VERSION "Vinfast Initial LGC"

NS_ :

BS_:

BU_: SCU BMS CHARGER HMI MCU TST

BO_ 3221225472 VECTOR__INDEPENDENT_SIG_MSG: 0 Vector__XXX
 SG_ scu_iso_signal : 0|64@0+ (1,0) [0|0] "" Vector__XXX
 SG_ scu_failflash : 0|4@0+ (1,0) [0|0] "" Vector__XXX
 SG_ SCU_Faildem1_accelerator : 0|8@0+ (1,0) [0|0] "" Vector__XXX
 SG_ bms_statusTemperaturePreFET : 0|8@0- (1,0) [-127|127] "กษ" Vector__XXX
 SG_ bms_statusTemperatureShunt : 0|8@0- (1,0) [-127|127] "กษ" Vector__XXX
 SG_ scu_commrequired_scu : 0|4@0+ (1,0) [0|15] "" Vector__XXX
 SG_ mcu_bootsubminor_version : 0|4@0+ (1,0) [0|0] "" Vector__XXX

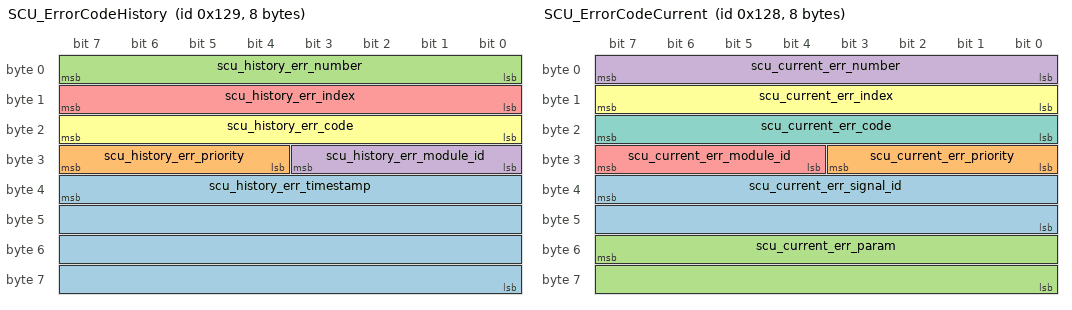
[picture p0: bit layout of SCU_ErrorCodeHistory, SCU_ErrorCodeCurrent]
BO_ 297 SCU_ErrorCodeHistory: 8 SCU
 SG_ scu_history_err_timestamp : 39|32@0+ (1,0) [0|4294967295] "" Vector__XXX
 SG_ scu_history_err_priority : 31|4@0+ (1,0) [0|15] "" Vector__XXX
 SG_ scu_history_err_number : 7|8@0+ (1,0) [0|255] "" Vector__XXX
 SG_ scu_history_err_module_id : 27|4@0+ (1,0) [0|15] "" Vector__XXX
 SG_ scu_history_err_index : 15|8@0+ (1,0) [0|255] "" Vector__XXX
 SG_ scu_history_err_code : 23|8@0+ (1,0) [0|255] "" Vector__XXX

BO_ 296 SCU_ErrorCodeCurrent: 8 SCU
 SG_ scu_current_err_signal_id : 39|16@0+ (1,0) [0|32767] "" Vector__XXX
 SG_ scu_current_err_priority : 27|4@0+ (1,0) [0|15] "" Vector__XXX
 SG_ scu_current_err_param : 55|16@0+ (1,0) [0|32767] "" Vector__XXX
 SG_ scu_current_err_number : 7|8@0+ (1,0) [0|255] "" Vector__XXX
 SG_ scu_current_err_module_id : 31|4@0+ (1,0) [0|15] "" Vector__XXX
 SG_ scu_current_err_index : 15|8@0+ (1,0) [0|255] "" Vector__XXX
 SG_ scu_current_err_code : 23|8@0- (1,0) [0|255] "" Vector__XXX

BO_ 262 SCU_Control_CHGWake: 8 SCU
 SG_ SCU_ctrl_chgWakePin : 3|4@0+ (1,0) [0|1] ""  CHARGER

BO_ 1 MCU_Iso_Message: 8 MCU
 SG_ mcu_iso_signal : 7|64@0+ (1,0) [0|0] ""  SCU

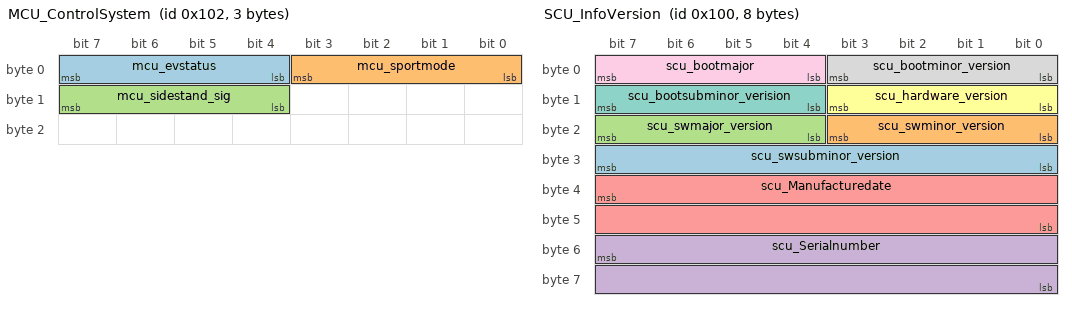
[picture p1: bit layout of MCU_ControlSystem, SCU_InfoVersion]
BO_ 258 MCU_ControlSystem: 3 MCU
 SG_ mcu_evstatus : 7|4@0+ (1,0) [0|0] ""  HMI,SCU
 SG_ mcu_sportmode : 3|4@0+ (1,0) [0|15] ""  HMI,SCU
 SG_ mcu_sidestand_sig : 15|4@0- (1,0) [0|1] ""  HMI,SCU

BO_ 256 SCU_InfoVersion: 8 SCU
 SG_ scu_swsubminor_version : 31|8@0+ (1,0) [0|0] "" Vector__XXX
 SG_ scu_swminor_version : 19|4@0+ (1,0) [0|0] "" Vector__XXX
 SG_ scu_swmajor_version : 23|4@0+ (1,0) [0|0] "" Vector__XXX
 SG_ scu_Serialnumber : 55|16@0+ (1,0) [0|0] "" Vector__XXX
 SG_ scu_Manufacturedate : 39|16@0+ (1,0) [0|0] "" Vector__XXX
 SG_ scu_hardware_version : 11|4@0+ (1,0) [0|0] "" Vector__XXX
 SG_ scu_bootsubminor_verision : 15|4@0+ (1,0) [0|0] "" Vector__XXX
 SG_ scu_bootminor_version : 3|4@0+ (1,0) [0|0] "" Vector__XXX
 SG_ scu_bootmajor : 7|4@0+ (1,0) [0|0] "" Vector__XXX

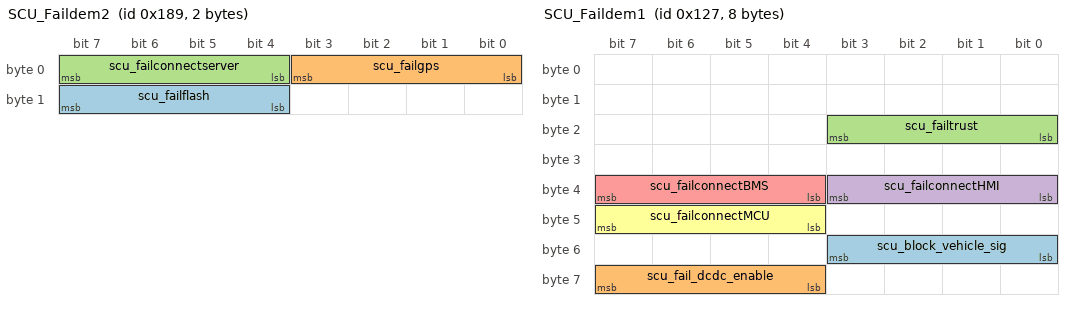
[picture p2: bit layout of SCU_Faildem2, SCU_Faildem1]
BO_ 393 SCU_Faildem2: 2 SCU
 SG_ scu_failflash : 15|4@0+ (1,0) [0|0] ""  HMI
 SG_ scu_failgps : 3|4@0+ (1,0) [0|0] ""  HMI
 SG_ scu_failconnectserver : 7|4@0+ (1,0) [0|0] ""  HMI

BO_ 295 SCU_Faildem1: 8 SCU
 SG_ scu_block_vehicle_sig : 51|4@0+ (1,0) [0|15] ""  HMI
 SG_ scu_fail_dcdc_enable : 63|4@0+ (1,0) [0|15] ""  HMI
 SG_ scu_failtrust : 19|4@0+ (1,0) [0|0] ""  HMI
 SG_ scu_failconnectHMI : 35|4@0+ (1,0) [0|0] ""  HMI
 SG_ scu_failconnectBMS : 39|4@0+ (1,0) [0|0] ""  HMI
 SG_ scu_failconnectMCU : 47|4@0+ (1,0) [0|0] ""  HMI

BO_ 386 SCU_Timestamp: 5 SCU
 SG_ scu_Time_Format : 39|4@0+ (1,0) [0|1] ""  HMI
 SG_ scu_epochtimestamp : 7|32@0+ (1,0) [0|0] ""  HMI

BO_ 270 SCU_Control_MCUData2: 8 SCU
 SG_ scu_ctrl_mcu_data2 : 7|64@0+ (1,0) [0|0] ""  MCU

BO_ 269 SCU_Control_MCUData1: 8 SCU
 SG_ scu_ctrl_mcu_data1 : 7|64@0+ (1,0) [0|0] ""  MCU

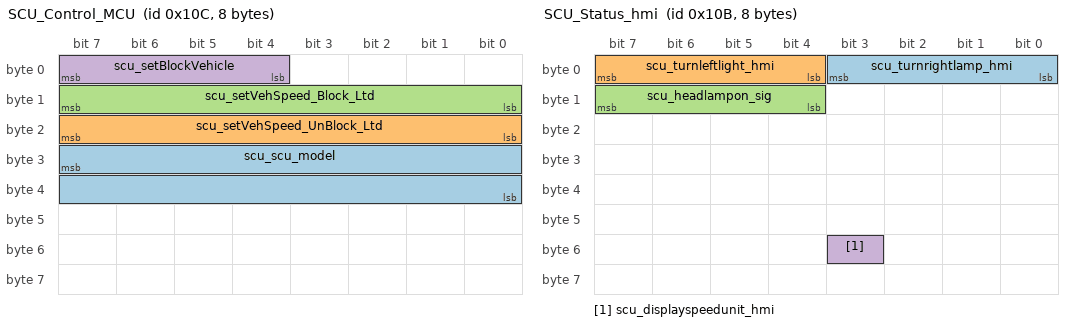
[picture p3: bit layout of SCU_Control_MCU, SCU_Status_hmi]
BO_ 268 SCU_Control_MCU: 8 SCU
 SG_ scu_scu_model : 31|16@0+ (1,0) [0|0] ""  MCU
 SG_ scu_setVehSpeed_UnBlock_Ltd : 23|8@0+ (1,0) [0|0] ""  MCU
 SG_ scu_setVehSpeed_Block_Ltd : 15|8@0+ (1,0) [0|0] ""  MCU
 SG_ scu_setBlockVehicle : 7|4@0+ (1,0) [0|0] ""  MCU

BO_ 517 MCU_SyncTimeData: 8 MCU
 SG_ mcu_sync_time_data : 7|64@0+ (1,0) [0|0] ""  SCU

BO_ 267 SCU_Status_hmi: 8 SCU
 SG_ scu_turnrightlamp_hmi : 3|4@0- (1,0) [0|0] ""  HMI
 SG_ scu_turnleftlight_hmi : 7|4@0+ (1,0) [0|0] ""  HMI
 SG_ scu_headlampon_sig : 15|4@0+ (1,0) [0|0] ""  HMI
 SG_ scu_displayspeedunit_hmi : 51|1@0+ (1,0) [0|0] ""  HMI

BO_ 261 SCU_Debug_Msg: 8 SCU
 SG_ SCU_state : 7|4@0+ (1,0) [0|0] "" Vector__XXX
 SG_ SCU_IG_status : 3|4@0+ (1,0) [0|0] "" Vector__XXX

BO_ 515 MCU_Request_ODO: 1 MCU
 SG_ mcu_request_odo_sig : 7|8@0+ (1,0) [0|0] ""  SCU

BO_ 264 SCU_SyncODO: 4 SCU
 SG_ scu_total_ODO : 7|32@0+ (1,0) [0|0] ""  MCU

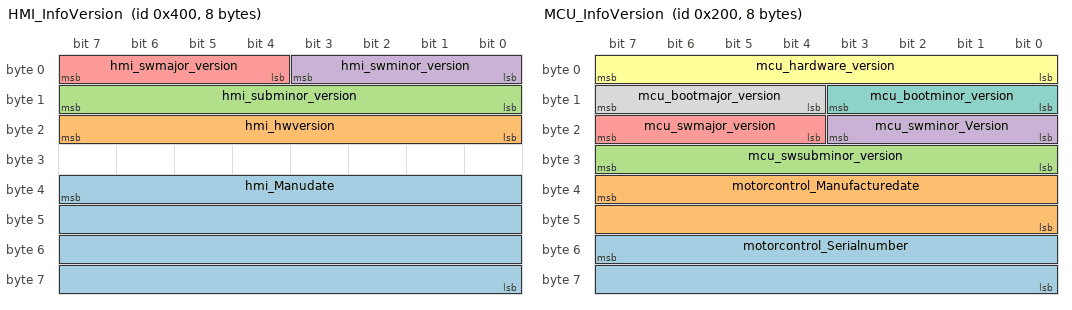
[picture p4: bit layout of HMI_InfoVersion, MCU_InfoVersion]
BO_ 1024 HMI_InfoVersion: 8 HMI
 SG_ hmi_Manudate : 39|32@0+ (1,0) [0|0] ""  SCU
 SG_ hmi_hwversion : 23|8@0+ (1,0) [0|0] ""  SCU
 SG_ hmi_subminor_version : 15|8@0+ (1,0) [0|0] ""  SCU
 SG_ hmi_swminor_version : 3|4@0+ (1,0) [0|0] ""  SCU
 SG_ hmi_swmajor_version : 7|4@0+ (1,0) [0|0] ""  SCU

BO_ 1026 HMI_Faildem: 1 HMI
 SG_ hmi_fail_canmcu : 7|4@0+ (1,0) [0|0] ""  SCU

BO_ 512 MCU_InfoVersion: 8 MCU
 SG_ motorcontrol_Serialnumber : 55|16@0+ (1,0) [0|0] ""  SCU
 SG_ motorcontrol_Manufacturedate : 39|16@0+ (1,0) [0|65535] ""  SCU
 SG_ mcu_swsubminor_version : 31|8@0+ (1,0) [0|255] ""  SCU
 SG_ mcu_swminor_Version : 19|4@0+ (1,0) [0|15] ""  SCU
 SG_ mcu_swmajor_version : 23|4@0+ (1,0) [0|0] ""  SCU
 SG_ mcu_hardware_version : 7|8@0+ (1,0) [0|0] ""  SCU
 SG_ mcu_bootminor_version : 11|4@0+ (1,0) [0|0] ""  SCU
 SG_ mcu_bootmajor_version : 15|4@0+ (1,0) [0|0] ""  SCU

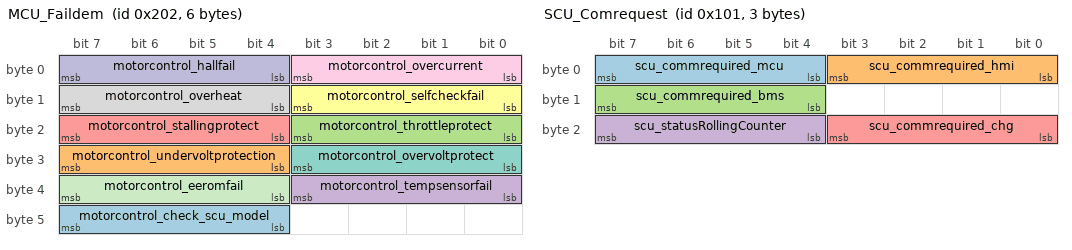
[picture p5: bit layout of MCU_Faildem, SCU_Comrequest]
BO_ 514 MCU_Faildem: 6 MCU
 SG_ motorcontrol_check_scu_model : 47|4@0+ (1,0) [0|0] ""  HMI,SCU
 SG_ motorcontrol_undervoltprotection : 31|4@0+ (1,0) [0|0] ""  SCU,HMI
 SG_ motorcontrol_throttleprotect : 19|4@0+ (1,0) [0|0] ""  SCU,HMI
 SG_ motorcontrol_tempsensorfail : 35|4@0+ (1,0) [0|0] ""  SCU,HMI
 SG_ motorcontrol_stallingprotect : 23|4@0+ (1,0) [0|0] ""  SCU,HMI
 SG_ motorcontrol_selfcheckfail : 11|4@0+ (1,0) [0|0] ""  SCU,HMI
 SG_ motorcontrol_overvoltprotect : 27|4@0+ (1,0) [0|0] ""  SCU,HMI
 SG_ motorcontrol_overheat : 15|4@0+ (1,0) [0|0] ""  SCU,HMI
 SG_ motorcontrol_overcurrent : 3|4@0+ (1,0) [0|0] ""  SCU,HMI
 SG_ motorcontrol_hallfail : 7|4@0+ (1,0) [0|15] ""  SCU,HMI
 SG_ motorcontrol_eeromfail : 39|4@0+ (1,0) [0|15] ""  SCU,HMI

BO_ 782 BMS_InfoContactor: 8 BMS
 SG_ bms_statusAdcPackVolt : 7|16@0+ (0.01,0) [0|655.35] "10mV"  SCU
 SG_ bms_statusAdcAfterFuseVolt : 39|16@0+ (0.01,0) [0|655.35] "10mV"  SCU
 SG_ bms_statusAdcAfterContactorVolt : 23|16@0+ (0.01,0) [0|655.35] "10mV"  SCU

BO_ 795 BMS_InfoVoltageCell6: 8 BMS
 SG_ bms_statusVoltageCell22 : 23|16@0+ (0.0001,0) [0|6.5535] "V"  SCU
 SG_ bms_statusVoltageCell21 : 7|16@0+ (0.0001,0) [0|6.5535] "V"  SCU

BO_ 794 BMS_InfoVoltageCell5: 8 BMS
 SG_ bms_statusVoltageCell20 : 55|16@0+ (0.0001,0) [0|6.5535] "V"  SCU
 SG_ bms_statusVoltageCell19 : 39|16@0+ (0.0001,0) [0|6.5535] "V"  SCU
 SG_ bms_statusVoltageCell18 : 23|16@0+ (0.0001,0) [0|6.5535] "V" Vector__XXX
 SG_ bms_statusVoltageCell17 : 7|16@0+ (0.0001,0) [0|6.5535] "V" Vector__XXX

BO_ 257 SCU_Comrequest: 3 SCU
 SG_ scu_commrequired_mcu : 7|4@0+ (1,0) [0|15] ""  MCU
 SG_ scu_commrequired_hmi : 3|4@0+ (1,0) [0|15] ""  HMI
 SG_ scu_commrequired_bms : 15|4@0+ (1,0) [0|15] ""  BMS
 SG_ scu_statusRollingCounter : 23|4@0+ (1,0) [0|15] "" Vector__XXX
 SG_ scu_commrequired_chg : 19|4@0+ (1,0) [0|15] ""  CHARGER

BO_ 271 SCU_info: 8 SCU
 SG_ scu_ignitionstatus_bms : 7|4@0+ (1,0) [0|15] ""  BMS
 SG_ scu_sendrollingcounter_bms : 3|4@0+ (1,0) [0|15] ""  BMS

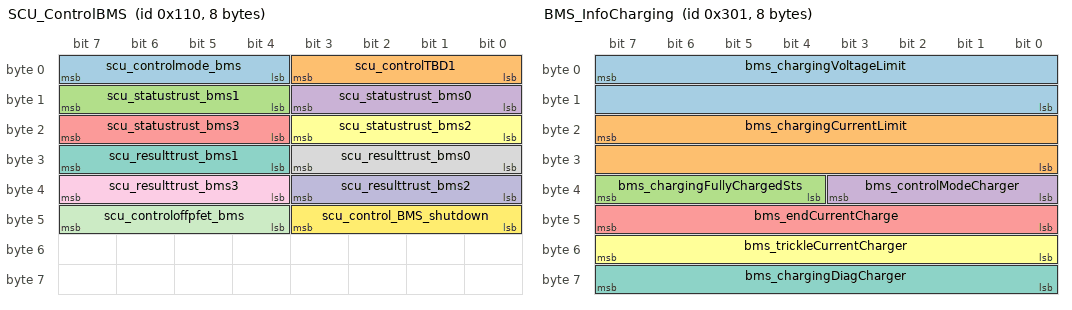
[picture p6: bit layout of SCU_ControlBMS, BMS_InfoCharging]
BO_ 272 SCU_ControlBMS: 8 SCU
 SG_ scu_controlmode_bms : 7|4@0+ (1,0) [0|15] ""  BMS
 SG_ scu_controlTBD1 : 3|4@0+ (1,0) [0|15] ""  BMS
 SG_ scu_statustrust_bms1 : 15|4@0+ (1,0) [0|15] ""  BMS
 SG_ scu_statustrust_bms0 : 11|4@0+ (1,0) [0|15] ""  BMS
 SG_ scu_statustrust_bms3 : 23|4@0+ (1,0) [0|15] ""  BMS
 SG_ scu_statustrust_bms2 : 19|4@0+ (1,0) [0|15] ""  BMS
 SG_ scu_resulttrust_bms1 : 31|4@0+ (1,0) [0|15] ""  BMS
 SG_ scu_resulttrust_bms0 : 27|4@0+ (1,0) [0|15] ""  BMS
 SG_ scu_resulttrust_bms3 : 39|4@0+ (1,0) [0|15] ""  BMS
 SG_ scu_resulttrust_bms2 : 35|4@0+ (1,0) [0|15] ""  BMS
 SG_ scu_controloffpfet_bms : 47|4@0+ (1,0) [0|15] ""  BMS
 SG_ scu_control_BMS_shutdown : 43|4@0+ (1,0) [0|15] ""  BMS

BO_ 2 BMS_ISO_Message: 8 BMS
 SG_ bms_iso_signal : 7|64@0+ (1,0) [0|1.84467440737096E+019] ""  CHARGER,SCU

BO_ 513 MCU_Infostatus: 8 MCU
 SG_ mcu_speedkmh : 7|16@0+ (1,0) [0|65535] ""  HMI,SCU
 SG_ mcu_totalODO : 23|32@0+ (1,0) [0|4294967295] ""  BMS,SCU,HMI
 SG_ mcu_brakesignal : 63|4@0+ (1,0) [0|15] ""  HMI

BO_ 768 BMS_ControlSystem: 8 BMS
 SG_ bms_controlSysMaxChgCurrent : 7|16@0- (0.02,0) [-655|655] "A"  CHARGER,MCU,SCU
 SG_ bms_controlSysMaxDsgCurrent : 23|16@0- (0.02,0) [-655|655] "A"  CHARGER,MCU,SCU
 SG_ bms_controlSysMaxChgPower : 39|16@0- (1,0) [-32767|32767] "W"  CHARGER,MCU,SCU
 SG_ bms_controlSysMaxDsgPower : 55|16@0- (1,0) [-32767|32767] "W"  CHARGER,MCU,SCU

BO_ 769 BMS_InfoCharging: 8 BMS
 SG_ bms_chargingVoltageLimit : 7|16@0+ (0.002,0) [0|131.07] "V"  CHARGER
 SG_ bms_chargingCurrentLimit : 23|16@0- (0.02,0) [-655|655] "A"  CHARGER
 SG_ bms_chargingFullyChargedSts : 39|4@0+ (1,0) [0|15] ""  CHARGER
 SG_ bms_controlModeCharger : 35|4@0+ (1,0) [0|15] ""  CHARGER
 SG_ bms_endCurrentCharge : 47|8@0+ (0.01,0) [0|2.55] "A"  CHARGER
 SG_ bms_trickleCurrentCharger : 55|8@0+ (0.01,0) [0|2.55] "A"  CHARGER
 SG_ bms_chargingDiagCharger : 63|8@0+ (1,0) [0|255] ""  CHARGER

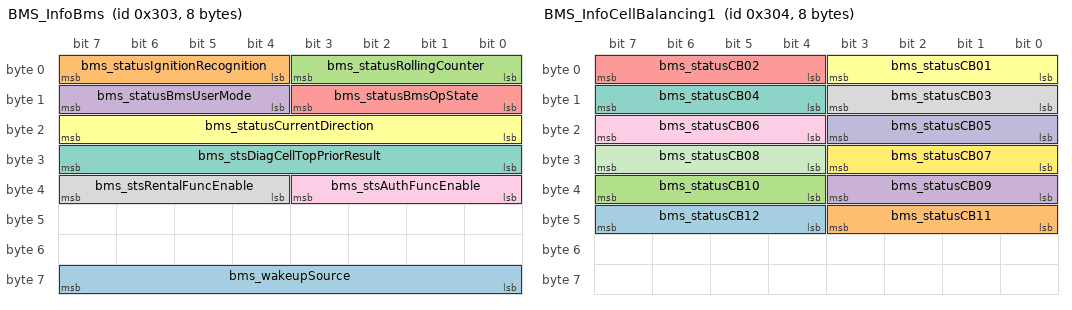
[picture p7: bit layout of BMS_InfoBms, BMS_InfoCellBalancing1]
BO_ 771 BMS_InfoBms: 8 BMS
 SG_ bms_wakeupSource : 63|8@0+ (1,0) [0|0] ""  SCU
 SG_ bms_statusIgnitionRecognition : 7|4@0+ (1,0) [0|15] ""  CHARGER,SCU
 SG_ bms_statusRollingCounter : 3|4@0+ (1,0) [0|15] ""  CHARGER,SCU
 SG_ bms_statusBmsUserMode : 15|4@0+ (1,0) [0|15] ""  CHARGER,SCU
 SG_ bms_statusBmsOpState : 11|4@0+ (1,0) [0|15] ""  CHARGER,SCU
 SG_ bms_statusCurrentDirection : 23|8@0+ (1,0) [0|255] ""  CHARGER,SCU
 SG_ bms_stsDiagCellTopPriorResult : 31|8@0+ (1,0) [0|255] ""  CHARGER,SCU
 SG_ bms_stsRentalFuncEnable : 39|4@0+ (1,0) [0|15] ""  CHARGER,SCU
 SG_ bms_stsAuthFuncEnable : 35|4@0+ (1,0) [0|15] ""  CHARGER,SCU

BO_ 772 BMS_InfoCellBalancing1: 8 BMS
 SG_ bms_statusCB12 : 47|4@0+ (1,0) [0|15] "" Vector__XXX
 SG_ bms_statusCB11 : 43|4@0+ (1,0) [0|15] "" Vector__XXX
 SG_ bms_statusCB10 : 39|4@0+ (1,0) [0|15] "" Vector__XXX
 SG_ bms_statusCB09 : 35|4@0+ (1,0) [0|15] "" Vector__XXX
 SG_ bms_statusCB02 : 7|4@0+ (1,0) [0|15] ""  SCU
 SG_ bms_statusCB01 : 3|4@0+ (1,0) [0|15] ""  SCU
 SG_ bms_statusCB04 : 15|4@0+ (1,0) [0|15] ""  SCU
 SG_ bms_statusCB03 : 11|4@0+ (1,0) [0|15] ""  SCU
 SG_ bms_statusCB06 : 23|4@0+ (1,0) [0|15] ""  SCU
 SG_ bms_statusCB05 : 19|4@0+ (1,0) [0|15] ""  SCU
 SG_ bms_statusCB08 : 31|4@0+ (1,0) [0|15] ""  SCU
 SG_ bms_statusCB07 : 27|4@0+ (1,0) [0|15] ""  SCU

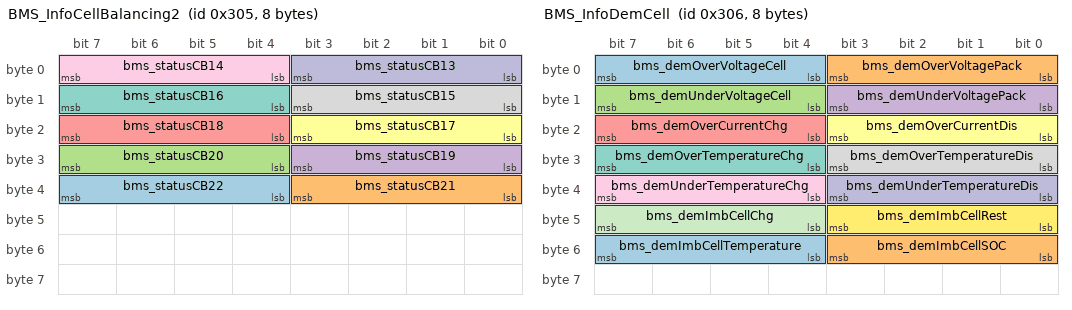
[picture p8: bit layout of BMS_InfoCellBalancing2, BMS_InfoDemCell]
BO_ 773 BMS_InfoCellBalancing2: 8 BMS
 SG_ bms_statusCB22 : 39|4@0+ (1,0) [0|15] ""  SCU
 SG_ bms_statusCB21 : 35|4@0+ (1,0) [0|15] ""  SCU
 SG_ bms_statusCB20 : 31|4@0+ (1,0) [0|15] ""  SCU
 SG_ bms_statusCB19 : 27|4@0+ (1,0) [0|15] ""  SCU
 SG_ bms_statusCB18 : 23|4@0+ (1,0) [0|15] "" Vector__XXX
 SG_ bms_statusCB17 : 19|4@0+ (1,0) [0|15] "" Vector__XXX
 SG_ bms_statusCB16 : 15|4@0+ (1,0) [0|15] "" Vector__XXX
 SG_ bms_statusCB15 : 11|4@0+ (1,0) [0|15] "" Vector__XXX
 SG_ bms_statusCB14 : 7|4@0+ (1,0) [0|15] ""  SCU
 SG_ bms_statusCB13 : 3|4@0+ (1,0) [0|15] ""  SCU

BO_ 774 BMS_InfoDemCell: 8 BMS
 SG_ bms_demOverVoltageCell : 7|4@0+ (1,0) [0|15] ""  HMI,SCU
 SG_ bms_demOverVoltagePack : 3|4@0+ (1,0) [0|15] ""  HMI,SCU
 SG_ bms_demUnderVoltageCell : 15|4@0+ (1,0) [0|15] ""  HMI,SCU
 SG_ bms_demUnderVoltagePack : 11|4@0+ (1,0) [0|15] ""  HMI,SCU
 SG_ bms_demOverCurrentChg : 23|4@0+ (1,0) [0|15] ""  HMI,SCU
 SG_ bms_demOverCurrentDis : 19|4@0+ (1,0) [0|15] ""  HMI,SCU
 SG_ bms_demOverTemperatureChg : 31|4@0+ (1,0) [0|15] ""  HMI,SCU
 SG_ bms_demOverTemperatureDis : 27|4@0+ (1,0) [0|15] ""  HMI,SCU
 SG_ bms_demUnderTemperatureChg : 39|4@0+ (1,0) [0|15] ""  HMI,SCU
 SG_ bms_demUnderTemperatureDis : 35|4@0+ (1,0) [0|15] ""  HMI,SCU
 SG_ bms_demImbCellChg : 47|4@0+ (1,0) [0|15] ""  HMI,SCU
 SG_ bms_demImbCellRest : 43|4@0+ (1,0) [0|15] ""  HMI,SCU
 SG_ bms_demImbCellTemperature : 55|4@0+ (1,0) [0|15] ""  HMI,SCU
 SG_ bms_demImbCellSOC : 51|4@0+ (1,0) [0|15] ""  HMI,SCU

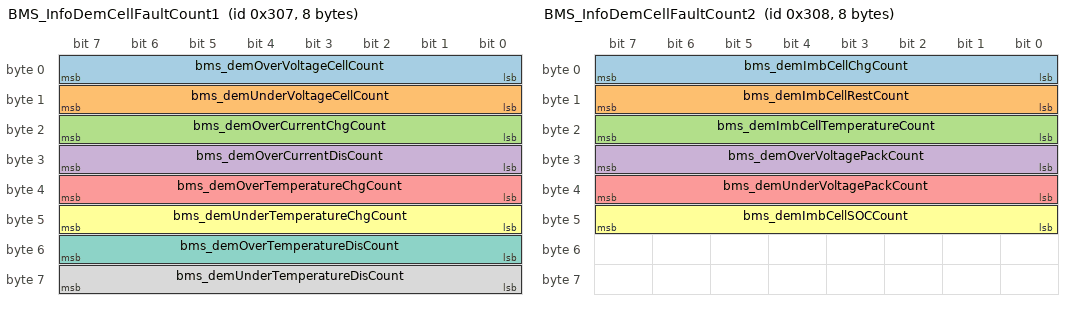
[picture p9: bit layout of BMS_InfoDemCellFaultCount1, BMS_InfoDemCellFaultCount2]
BO_ 775 BMS_InfoDemCellFaultCount1: 8 BMS
 SG_ bms_demOverVoltageCellCount : 7|8@0+ (1,0) [0|255] ""  SCU
 SG_ bms_demUnderVoltageCellCount : 15|8@0+ (1,0) [0|255] ""  SCU
 SG_ bms_demOverCurrentChgCount : 23|8@0+ (1,0) [0|255] ""  SCU
 SG_ bms_demOverCurrentDisCount : 31|8@0+ (1,0) [0|255] ""  SCU
 SG_ bms_demOverTemperatureChgCount : 39|8@0+ (1,0) [0|255] ""  SCU
 SG_ bms_demUnderTemperatureChgCount : 47|8@0+ (1,0) [0|255] ""  SCU
 SG_ bms_demOverTemperatureDisCount : 55|8@0+ (1,0) [0|255] ""  SCU
 SG_ bms_demUnderTemperatureDisCount : 63|8@0+ (1,0) [0|255] ""  SCU

BO_ 776 BMS_InfoDemCellFaultCount2: 8 BMS
 SG_ bms_demImbCellChgCount : 7|8@0+ (1,0) [0|255] ""  SCU
 SG_ bms_demImbCellRestCount : 15|8@0+ (1,0) [0|255] ""  SCU
 SG_ bms_demImbCellTemperatureCount : 23|8@0+ (1,0) [0|255] ""  SCU
 SG_ bms_demOverVoltagePackCount : 31|8@0+ (1,0) [0|255] ""  SCU
 SG_ bms_demUnderVoltagePackCount : 39|8@0+ (1,0) [0|255] ""  SCU
 SG_ bms_demImbCellSOCCount : 47|8@0+ (1,0) [0|255] ""  SCU

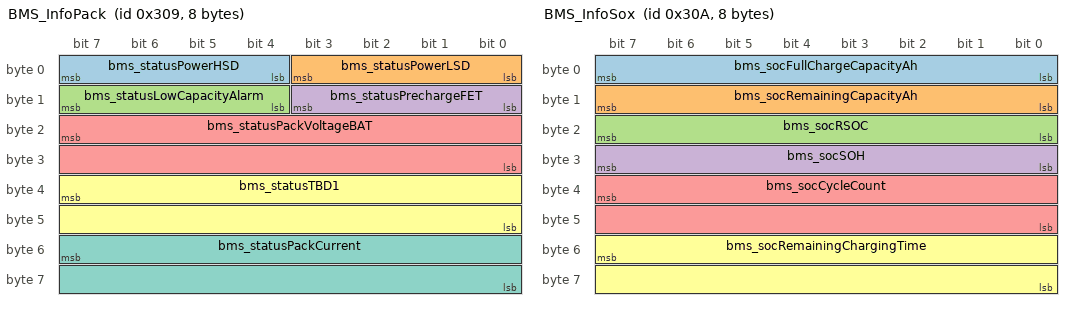
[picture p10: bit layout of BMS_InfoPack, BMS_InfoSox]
BO_ 777 BMS_InfoPack: 8 BMS
 SG_ bms_statusPowerHSD : 7|4@0+ (1,0) [0|15] ""  CHARGER,SCU
 SG_ bms_statusPowerLSD : 3|4@0+ (1,0) [0|15] ""  CHARGER,SCU
 SG_ bms_statusLowCapacityAlarm : 15|4@0+ (1,0) [0|15] ""  CHARGER,SCU
 SG_ bms_statusPrechargeFET : 11|4@0+ (1,0) [0|15] ""  CHARGER,SCU
 SG_ bms_statusPackVoltageBAT : 23|16@0+ (0.002,0) [0|131.07] "V"  CHARGER,HMI,SCU
 SG_ bms_statusTBD1 : 39|16@0+ (1,0) [0|65535] ""  CHARGER,HMI,SCU
 SG_ bms_statusPackCurrent : 55|16@0- (0.02,0) [-655.36|655.34] "A"  CHARGER,HMI,SCU

BO_ 778 BMS_InfoSox: 8 BMS
 SG_ bms_socFullChargeCapacityAh : 7|8@0+ (0.4,0) [0|76.5] "Ah"  CHARGER,SCU
 SG_ bms_socRemainingCapacityAh : 15|8@0+ (0.4,0) [0|102] "Ah"  CHARGER,SCU
 SG_ bms_socRSOC : 23|8@0+ (1,0) [0|255] "%"  CHARGER,HMI,SCU
 SG_ bms_socSOH : 31|8@0+ (1,0) [0|255] "%"  CHARGER,HMI,SCU
 SG_ bms_socCycleCount : 39|16@0+ (1,0) [0|65535] ""  CHARGER,HMI,SCU
 SG_ bms_socRemainingChargingTime : 55|16@0+ (1,0) [0|65535] "min"  CHARGER,HMI,SCU

BO_ 779 BMS_InfoAccumDsgChgCapacity: 8 BMS
 SG_ bms_AccumChargeCapacityAh : 7|32@0+ (1,0) [0|4294967295] "Ah"  SCU
 SG_ bms_AccumDischargeCapacityAh : 39|32@0+ (1,0) [0|4294967295] "Ah"  SCU

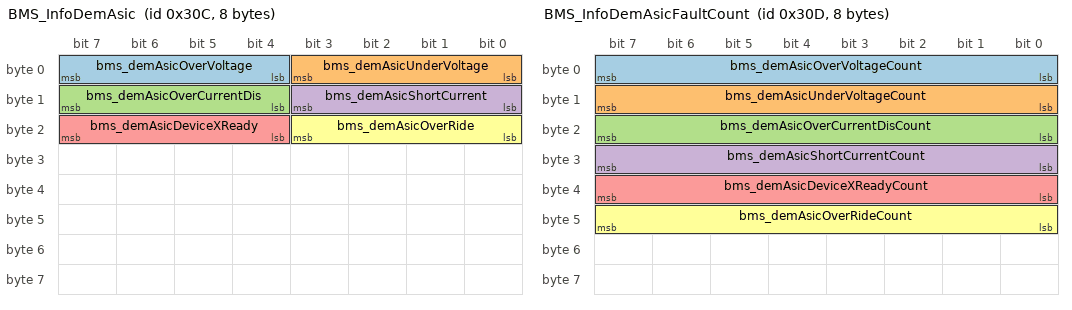
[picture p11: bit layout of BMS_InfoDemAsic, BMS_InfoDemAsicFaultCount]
BO_ 780 BMS_InfoDemAsic: 8 BMS
 SG_ bms_demAsicOverVoltage : 7|4@0+ (1,0) [0|15] ""  HMI,SCU
 SG_ bms_demAsicUnderVoltage : 3|4@0+ (1,0) [0|15] ""  HMI,SCU
 SG_ bms_demAsicOverCurrentDis : 15|4@0+ (1,0) [0|15] ""  HMI,SCU
 SG_ bms_demAsicShortCurrent : 11|4@0+ (1,0) [0|15] ""  HMI,SCU
 SG_ bms_demAsicDeviceXReady : 23|4@0+ (1,0) [0|15] ""  HMI,SCU
 SG_ bms_demAsicOverRide : 19|4@0+ (1,0) [0|15] ""  HMI,SCU

BO_ 781 BMS_InfoDemAsicFaultCount: 8 BMS
 SG_ bms_demAsicOverVoltageCount : 7|8@0+ (1,0) [0|255] ""  SCU
 SG_ bms_demAsicUnderVoltageCount : 15|8@0+ (1,0) [0|255] ""  SCU
 SG_ bms_demAsicOverCurrentDisCount : 23|8@0+ (1,0) [0|255] ""  SCU
 SG_ bms_demAsicShortCurrentCount : 31|8@0+ (1,0) [0|255] ""  SCU
 SG_ bms_demAsicDeviceXReadyCount : 39|8@0+ (1,0) [0|255] "" Vector__XXX
 SG_ bms_demAsicOverRideCount : 47|8@0+ (1,0) [0|255] ""  SCU

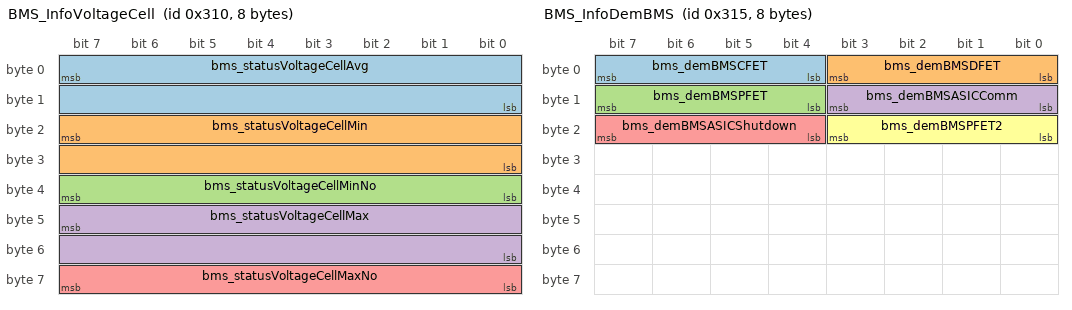
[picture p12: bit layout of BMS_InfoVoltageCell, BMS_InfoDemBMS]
BO_ 784 BMS_InfoVoltageCell: 8 BMS
 SG_ bms_statusVoltageCellAvg : 7|16@0+ (0.0001,0) [0|6.5535] "V"  SCU
 SG_ bms_statusVoltageCellMin : 23|16@0+ (0.0001,0) [0|6.5535] "V"  SCU
 SG_ bms_statusVoltageCellMinNo : 39|8@0+ (1,0) [0|255] "Bank"  SCU
 SG_ bms_statusVoltageCellMax : 47|16@0+ (0.0001,0) [0|6.5535] "V"  SCU
 SG_ bms_statusVoltageCellMaxNo : 63|8@0+ (1,0) [0|255] "Bank"  SCU

BO_ 785 BMS_InfoVoltageCell1: 8 BMS
 SG_ bms_statusVoltageCell01 : 7|16@0+ (0.0001,0) [0|6.5535] "V"  SCU
 SG_ bms_statusVoltageCell02 : 23|16@0+ (0.0001,0) [0|6.5535] "V"  SCU
 SG_ bms_statusVoltageCell03 : 39|16@0+ (0.0001,0) [0|6.5535] "V"  SCU
 SG_ bms_statusVoltageCell04 : 55|16@0+ (0.0001,0) [0|6.5535] "V"  SCU

BO_ 786 BMS_InfoVoltageCell2: 8 BMS
 SG_ bms_statusVoltageCell05 : 7|16@0+ (0.0001,0) [0|6.5535] "V"  SCU
 SG_ bms_statusVoltageCell06 : 23|16@0+ (0.0001,0) [0|6.5535] "V"  SCU
 SG_ bms_statusVoltageCell07 : 39|16@0+ (0.0001,0) [0|6.5535] "V"  SCU
 SG_ bms_statusVoltageCell08 : 55|16@0+ (0.0001,0) [0|6.5535] "V"  SCU

BO_ 787 BMS_InfoVoltageCell3: 8 BMS
 SG_ bms_statusVoltageCell09 : 7|16@0+ (0.0001,0) [0|6.5535] "V"  SCU
 SG_ bms_statusVoltageCell10 : 23|16@0+ (0.0001,0) [0|6.5535] "V"  SCU
 SG_ bms_statusVoltageCell11 : 39|16@0+ (0.0001,0) [0|6.5535] "V"  SCU
 SG_ bms_statusVoltageCell12 : 55|16@0+ (0.0001,0) [0|6.5535] "V"  SCU

BO_ 788 BMS_InfoVoltageCell4: 8 BMS
 SG_ bms_statusVoltageCell16 : 55|16@0+ (0.0001,0) [0|6.5535] "V" Vector__XXX
 SG_ bms_statusVoltageCell15 : 39|16@0+ (0.0001,0) [0|6.5535] "V" Vector__XXX
 SG_ bms_statusVoltageCell13 : 7|16@0+ (0.0001,0) [0|6.5535] "V"  SCU
 SG_ bms_statusVoltageCell14 : 23|16@0+ (0.0001,0) [0|6.5535] "V"  SCU

BO_ 789 BMS_InfoDemBMS: 8 BMS
 SG_ bms_demBMSCFET : 7|4@0+ (1,0) [0|15] ""  HMI,SCU
 SG_ bms_demBMSDFET : 3|4@0+ (1,0) [0|15] ""  HMI,SCU
 SG_ bms_demBMSPFET : 15|4@0+ (1,0) [0|15] ""  HMI,SCU
 SG_ bms_demBMSASICComm : 11|4@0+ (1,0) [0|15] ""  HMI,SCU
 SG_ bms_demBMSASICShutdown : 23|4@0+ (1,0) [0|15] ""  HMI,SCU
 SG_ bms_demBMSPFET2 : 19|4@0+ (1,0) [0|15] ""  SCU

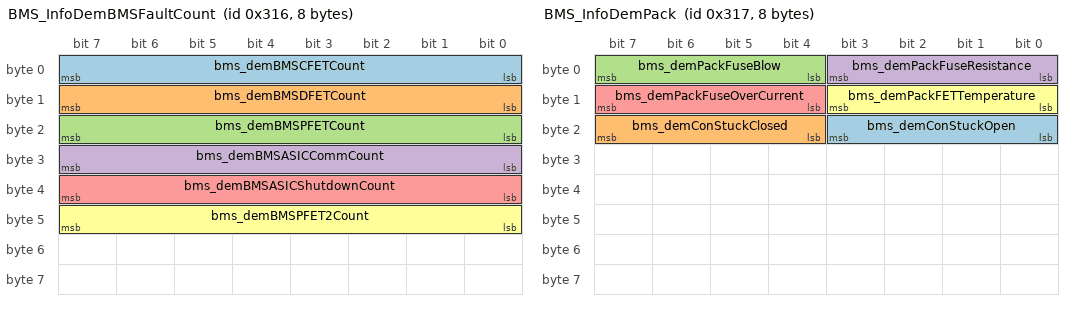
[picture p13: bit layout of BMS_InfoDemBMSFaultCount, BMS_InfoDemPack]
BO_ 790 BMS_InfoDemBMSFaultCount: 8 BMS
 SG_ bms_demBMSCFETCount : 7|8@0+ (1,0) [0|255] ""  SCU
 SG_ bms_demBMSDFETCount : 15|8@0+ (1,0) [0|255] ""  SCU
 SG_ bms_demBMSPFETCount : 23|8@0+ (1,0) [0|255] ""  SCU
 SG_ bms_demBMSASICCommCount : 31|8@0+ (1,0) [0|255] ""  SCU
 SG_ bms_demBMSASICShutdownCount : 39|8@0+ (1,0) [0|255] ""  SCU
 SG_ bms_demBMSPFET2Count : 47|8@0+ (1,0) [0|255] ""  SCU

BO_ 791 BMS_InfoDemPack: 8 BMS
 SG_ bms_demConStuckOpen : 19|4@0+ (1,0) [0|15] ""  SCU
 SG_ bms_demConStuckClosed : 23|4@0+ (1,0) [0|15] ""  SCU
 SG_ bms_demPackFuseBlow : 7|4@0+ (1,0) [0|15] ""  HMI,SCU
 SG_ bms_demPackFuseResistance : 3|4@0+ (1,0) [0|15] ""  HMI,SCU
 SG_ bms_demPackFuseOverCurrent : 15|4@0+ (1,0) [0|15] ""  HMI,SCU
 SG_ bms_demPackFETTemperature : 11|4@0+ (1,0) [0|15] ""  HMI,SCU

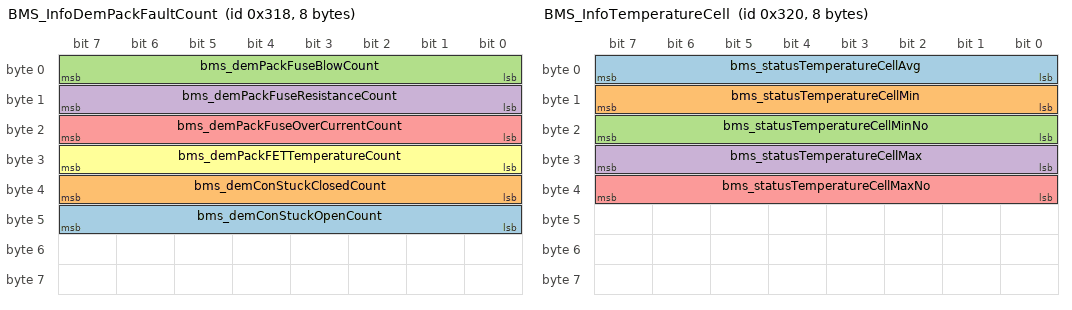
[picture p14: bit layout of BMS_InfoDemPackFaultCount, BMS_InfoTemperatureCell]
BO_ 792 BMS_InfoDemPackFaultCount: 8 BMS
 SG_ bms_demConStuckOpenCount : 47|8@0+ (1,0) [0|255] ""  SCU
 SG_ bms_demConStuckClosedCount : 39|8@0+ (1,0) [0|255] ""  SCU
 SG_ bms_demPackFuseBlowCount : 7|8@0+ (1,0) [0|255] ""  SCU
 SG_ bms_demPackFuseResistanceCount : 15|8@0+ (1,0) [0|255] ""  SCU
 SG_ bms_demPackFuseOverCurrentCount : 23|8@0+ (1,0) [0|255] ""  SCU
 SG_ bms_demPackFETTemperatureCount : 31|8@0+ (1,0) [0|255] ""  SCU

BO_ 793 BMS_InfoMileage: 8 BMS
 SG_ bms_mileage_data : 7|32@0+ (1,0) [0|4294967295] ""  SCU
 SG_ bms_mileageTBD1 : 39|32@0+ (1,0) [0|4294967295] ""  SCU

BO_ 800 BMS_InfoTemperatureCell: 8 BMS
 SG_ bms_statusTemperatureCellAvg : 7|8@0- (1,0) [-127|127] "กษ"  HMI,SCU
 SG_ bms_statusTemperatureCellMin : 15|8@0- (1,0) [-127|127] "กษ"  SCU
 SG_ bms_statusTemperatureCellMinNo : 23|8@0+ (1,0) [0|255] "Th"  SCU
 SG_ bms_statusTemperatureCellMax : 31|8@0- (1,0) [-127|127] "กษ"  HMI,SCU
 SG_ bms_statusTemperatureCellMaxNo : 39|8@0+ (1,0) [0|255] "Th"  SCU

BO_ 801 BMS_InfoTemperatureCell1: 8 BMS
 SG_ bms_statusTemperatureCell4 : 31|8@0- (1,0) [-127|127] "กษ"  SCU
 SG_ bms_statusTemperatureCell1 : 7|8@0- (1,0) [-127|127] "กษ"  SCU
 SG_ bms_statusTemperatureCell2 : 15|8@0- (1,0) [-127|127] "กษ"  SCU
 SG_ bms_statusTemperatureCell3 : 23|8@0- (1,0) [-127|127] "กษ"  SCU

BO_ 802 BMS_InfoTemperatureCB: 8 BMS
 SG_ bms_statusTemperatureCB4 : 31|8@0- (1,0) [-127|127] "กษ"  SCU
 SG_ bms_statusTemperatureCB3 : 23|8@0- (1,0) [-127|127] "กษ"  SCU
 SG_ bms_statusTemperatureCB1 : 7|8@0- (1,0) [-127|127] "กษ"  SCU
 SG_ bms_statusTemperatureCB2 : 15|8@0- (1,0) [-127|127] "กษ"  SCU

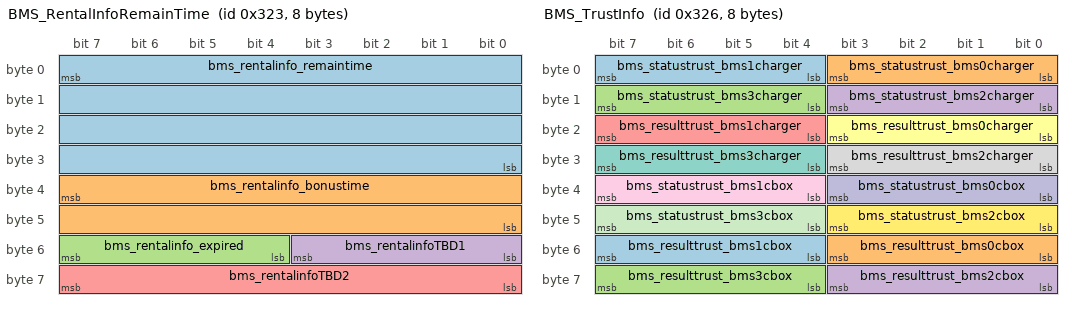
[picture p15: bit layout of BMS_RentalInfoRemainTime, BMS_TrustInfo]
BO_ 803 BMS_RentalInfoRemainTime: 8 BMS
 SG_ bms_rentalinfo_remaintime : 7|32@0+ (1,0) [0|4294967295] ""  SCU
 SG_ bms_rentalinfo_bonustime : 39|16@0+ (1,0) [0|65535] ""  SCU
 SG_ bms_rentalinfo_expired : 55|4@0+ (1,0) [0|15] ""  SCU
 SG_ bms_rentalinfoTBD1 : 51|4@0+ (1,0) [0|15] ""  SCU
 SG_ bms_rentalinfoTBD2 : 63|8@0+ (1,0) [0|255] ""  SCU

BO_ 804 BMS_RentalInfoCustomer1: 8 BMS
 SG_ bms_rentalinfo_customer1 : 7|32@0+ (1,0) [0|4294967295] ""  SCU
 SG_ bms_rentalinfo_customer12 : 39|32@0+ (1,0) [0|4294967295] ""  SCU

BO_ 805 BMS_RentalInfoCustomer2: 8 BMS
 SG_ bms_rentalinfo_customer2 : 7|32@0+ (1,0) [0|4294967295] ""  SCU
 SG_ bms_rentalinfo_customer22 : 39|32@0+ (1,0) [0|4294967295] ""  SCU

BO_ 806 BMS_TrustInfo: 8 BMS
 SG_ bms_statustrust_bms1charger : 7|4@0+ (1,0) [0|15] ""  CHARGER,SCU
 SG_ bms_statustrust_bms0charger : 3|4@0+ (1,0) [0|15] ""  CHARGER,SCU
 SG_ bms_statustrust_bms3charger : 15|4@0+ (1,0) [0|15] ""  CHARGER,SCU
 SG_ bms_statustrust_bms2charger : 11|4@0+ (1,0) [0|15] ""  CHARGER,SCU
 SG_ bms_resulttrust_bms1charger : 23|4@0+ (1,0) [0|15] ""  CHARGER,SCU
 SG_ bms_resulttrust_bms0charger : 19|4@0+ (1,0) [0|15] ""  CHARGER,SCU
 SG_ bms_resulttrust_bms3charger : 31|4@0+ (1,0) [0|15] ""  CHARGER,SCU
 SG_ bms_resulttrust_bms2charger : 27|4@0+ (1,0) [0|15] ""  CHARGER,SCU
 SG_ bms_statustrust_bms1cbox : 39|4@0+ (1,0) [0|15] ""  CHARGER,SCU
 SG_ bms_statustrust_bms0cbox : 35|4@0+ (1,0) [0|15] ""  CHARGER,SCU
 SG_ bms_statustrust_bms3cbox : 47|4@0+ (1,0) [0|15] ""  CHARGER,SCU
 SG_ bms_statustrust_bms2cbox : 43|4@0+ (1,0) [0|15] ""  CHARGER,SCU
 SG_ bms_resulttrust_bms1cbox : 55|4@0+ (1,0) [0|15] ""  CHARGER,SCU
 SG_ bms_resulttrust_bms0cbox : 51|4@0+ (1,0) [0|15] ""  CHARGER,SCU
 SG_ bms_resulttrust_bms3cbox : 63|4@0+ (1,0) [0|15] ""  CHARGER,SCU
 SG_ bms_resulttrust_bms2cbox : 59|4@0+ (1,0) [0|15] ""  CHARGER,SCU

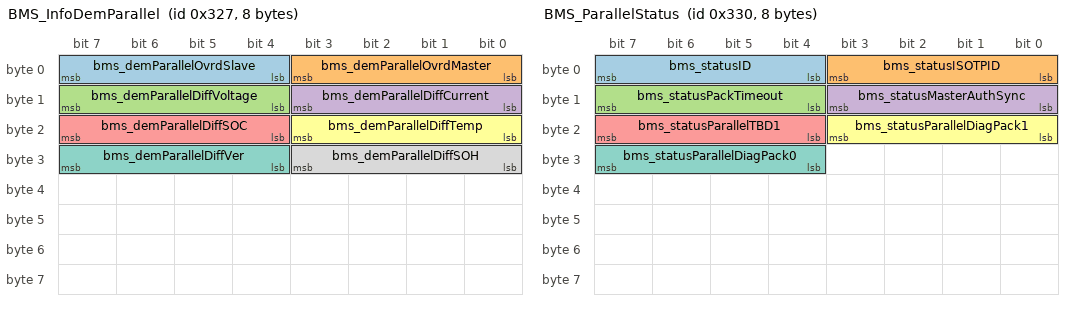
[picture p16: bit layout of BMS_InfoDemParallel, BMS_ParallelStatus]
BO_ 807 BMS_InfoDemParallel: 8 BMS
 SG_ bms_demParallelOvrdSlave : 7|4@0+ (1,0) [0|15] ""  CHARGER,SCU
 SG_ bms_demParallelOvrdMaster : 3|4@0+ (1,0) [0|15] ""  CHARGER,SCU
 SG_ bms_demParallelDiffVoltage : 15|4@0+ (1,0) [0|15] ""  CHARGER,SCU
 SG_ bms_demParallelDiffCurrent : 11|4@0+ (1,0) [0|15] ""  CHARGER,SCU
 SG_ bms_demParallelDiffSOC : 23|4@0+ (1,0) [0|15] ""  CHARGER,SCU
 SG_ bms_demParallelDiffTemp : 19|4@0+ (1,0) [0|15] ""  CHARGER,SCU
 SG_ bms_demParallelDiffVer : 31|4@0+ (1,0) [0|15] ""  CHARGER,SCU
 SG_ bms_demParallelDiffSOH : 27|4@0+ (1,0) [0|15] ""  CHARGER,SCU

BO_ 816 BMS_ParallelStatus: 8 BMS
 SG_ bms_statusID : 7|4@0+ (1,0) [0|15] ""  CHARGER,SCU
 SG_ bms_statusISOTPID : 3|4@0+ (1,0) [0|15] ""  CHARGER,SCU
 SG_ bms_statusPackTimeout : 15|4@0+ (1,0) [0|15] ""  CHARGER,SCU
 SG_ bms_statusMasterAuthSync : 11|4@0+ (1,0) [0|15] ""  CHARGER,SCU
 SG_ bms_statusParallelTBD1 : 23|4@0+ (1,0) [0|15] ""  CHARGER,SCU
 SG_ bms_statusParallelDiagPack1 : 19|4@0+ (1,0) [0|15] ""  CHARGER,SCU
 SG_ bms_statusParallelDiagPack0 : 31|4@0+ (1,0) [0|15] ""  CHARGER,SCU

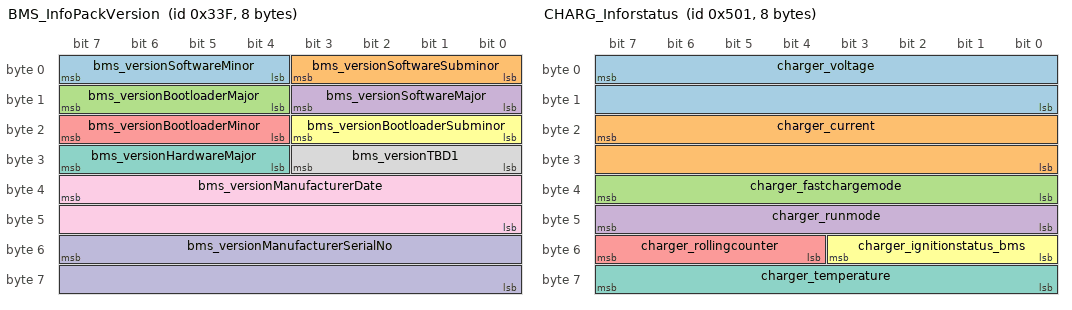
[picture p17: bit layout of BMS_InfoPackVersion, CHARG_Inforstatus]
BO_ 831 BMS_InfoPackVersion: 8 BMS
 SG_ bms_versionSoftwareMinor : 7|4@0+ (1,0) [0|15] ""  CHARGER,SCU
 SG_ bms_versionSoftwareSubminor : 3|4@0+ (1,0) [0|15] ""  CHARGER,SCU
 SG_ bms_versionBootloaderMajor : 15|4@0+ (1,0) [0|15] ""  CHARGER,SCU
 SG_ bms_versionSoftwareMajor : 11|4@0+ (1,0) [0|15] ""  CHARGER,SCU
 SG_ bms_versionBootloaderMinor : 23|4@0+ (1,0) [0|15] ""  CHARGER,SCU
 SG_ bms_versionBootloaderSubminor : 19|4@0+ (1,0) [0|15] ""  CHARGER,SCU
 SG_ bms_versionHardwareMajor : 31|4@0+ (1,0) [0|15] ""  CHARGER,SCU
 SG_ bms_versionTBD1 : 27|4@0+ (1,0) [0|15] ""  CHARGER,SCU
 SG_ bms_versionManufacturerDate : 39|16@0+ (1,0) [0|65535] ""  CHARGER,SCU
 SG_ bms_versionManufacturerSerialNo : 55|16@0+ (1,0) [0|65535] ""  CHARGER,SCU

BO_ 1281 CHARG_Inforstatus: 8 CHARGER
 SG_ charger_voltage : 7|16@0+ (0.1,0) [0|6553.5] ""  SCU
 SG_ charger_current : 23|16@0- (0.1,0) [-3276|3276] ""  SCU
 SG_ charger_fastchargemode : 39|8@0+ (1,0) [0|255] "" Vector__XXX
 SG_ charger_runmode : 47|8@0+ (1,0) [0|255] ""  HMI
 SG_ charger_rollingcounter : 55|4@0+ (1,0) [0|15] "" Vector__XXX
 SG_ charger_ignitionstatus_bms : 51|4@0+ (1,0) [0|15] ""  BMS
 SG_ charger_temperature : 63|8@0+ (1,0) [0|255] ""  SCU

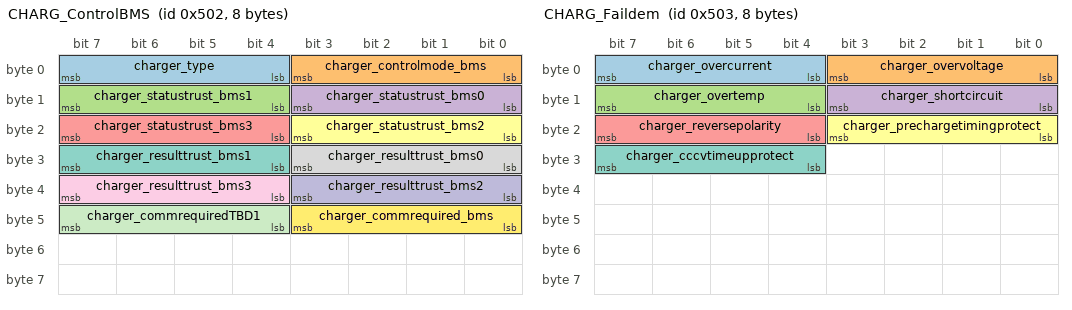
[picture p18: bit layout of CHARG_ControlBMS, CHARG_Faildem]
BO_ 1282 CHARG_ControlBMS: 8 CHARGER
 SG_ charger_type : 7|4@0+ (1,0) [0|15] "" Vector__XXX
 SG_ charger_controlmode_bms : 3|4@0- (1,0) [-7|7] ""  SCU,HMI,BMS
 SG_ charger_statustrust_bms1 : 15|4@0+ (1,0) [0|15] ""  BMS
 SG_ charger_statustrust_bms0 : 11|4@0+ (1,0) [0|15] ""  BMS
 SG_ charger_statustrust_bms3 : 23|4@0+ (1,0) [0|15] ""  BMS
 SG_ charger_statustrust_bms2 : 19|4@0+ (1,0) [0|15] ""  BMS
 SG_ charger_resulttrust_bms1 : 31|4@0+ (1,0) [0|15] ""  BMS
 SG_ charger_resulttrust_bms0 : 27|4@0+ (1,0) [0|15] ""  BMS
 SG_ charger_resulttrust_bms3 : 39|4@0+ (1,0) [0|15] ""  BMS
 SG_ charger_resulttrust_bms2 : 35|4@0+ (1,0) [0|15] ""  BMS
 SG_ charger_commrequiredTBD1 : 47|4@0+ (1,0) [0|15] ""  BMS
 SG_ charger_commrequired_bms : 43|4@0+ (1,0) [0|15] ""  BMS

BO_ 1283 CHARG_Faildem: 8 CHARGER
 SG_ charger_overcurrent : 7|4@0+ (1,0) [0|15] ""  HMI,BMS,SCU
 SG_ charger_overvoltage : 3|4@0+ (1,0) [0|15] ""  HMI,BMS,SCU
 SG_ charger_overtemp : 15|4@0+ (1,0) [0|15] ""  HMI,BMS,SCU
 SG_ charger_shortcircuit : 11|4@0+ (1,0) [0|15] ""  HMI,BMS,SCU
 SG_ charger_reversepolarity : 23|4@0+ (1,0) [0|15] ""  HMI,BMS,SCU
 SG_ charger_prechargetimingprotect : 19|4@0+ (1,0) [0|15] ""  HMI,BMS,SCU
 SG_ charger_cccvtimeupprotect : 31|4@0+ (1,0) [0|15] ""  HMI,BMS,SCU

BO_ 6 SCU_ISO_Message: 8 SCU
 SG_ scu_iso_signal : 7|64@0+ (1,0) [0|1.84467440737096E+019] ""  BMS,MCU

BO_ 9 CHARG_ISO_Message: 8 CHARGER
 SG_ charger_iso_signal : 7|64@0+ (1,0) [0|1.84467440737096E+019] ""  BMS

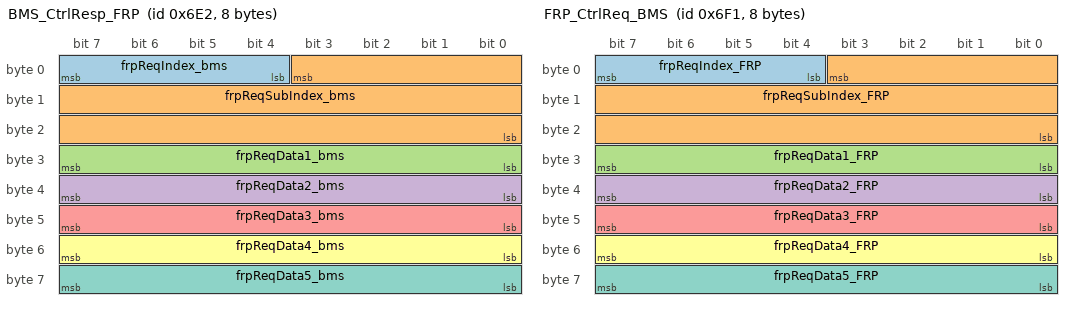
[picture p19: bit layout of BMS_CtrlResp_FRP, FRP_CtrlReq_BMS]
BO_ 1762 BMS_CtrlResp_FRP: 8 BMS
 SG_ frpReqIndex_bms : 7|4@0+ (1,0) [0|15] ""  TST
 SG_ frpReqSubIndex_bms : 3|20@0+ (1,0) [0|1048575] ""  TST
 SG_ frpReqData1_bms : 31|8@0+ (1,0) [0|255] ""  TST
 SG_ frpReqData2_bms : 39|8@0+ (1,0) [0|255] ""  TST
 SG_ frpReqData3_bms : 47|8@0+ (1,0) [0|255] ""  TST
 SG_ frpReqData4_bms : 55|8@0+ (1,0) [0|255] ""  TST
 SG_ frpReqData5_bms : 63|8@0+ (1,0) [0|255] ""  TST

BO_ 1777 FRP_CtrlReq_BMS: 8 TST
 SG_ frpReqIndex_FRP : 7|4@0+ (1,0) [0|15] ""  BMS
 SG_ frpReqSubIndex_FRP : 3|20@0+ (1,0) [0|1048575] ""  BMS
 SG_ frpReqData1_FRP : 31|8@0+ (1,0) [0|255] ""  BMS
 SG_ frpReqData2_FRP : 39|8@0+ (1,0) [0|255] ""  BMS
 SG_ frpReqData3_FRP : 47|8@0+ (1,0) [0|255] ""  BMS
 SG_ frpReqData4_FRP : 55|8@0+ (1,0) [0|255] ""  BMS
 SG_ frpReqData5_FRP : 63|8@0+ (1,0) [0|255] ""  BMS

CM_ BU_ SCU "Vehicle control unit (Suzuki)";
CM_ BU_ BMS "48V Battery Module Master (LGC)";
CM_ BU_ CHARGER "CHARGER";
CM_ BU_ HMI "HMI";
CM_ BU_ MCU "MCU";
CM_ BU_ TST "TST";
CM_ BO_ 3221225472 "This is a message for not used signals, created by Vector CANdb++ DBC OLE DB Provider.";
CM_ SG_ 3221225472 bms_statusTemperaturePreFET "Max) Temperature - Power FET Temperature";
CM_ SG_ 3221225472 bms_statusTemperatureShunt "Max) Temperature - Power FET Temperature";
CM_ SG_ 262 SCU_ctrl_chgWakePin "1: Floating wake up pin of charger
0: Pull up wake up pin of charger";
CM_ SG_ 258 mcu_evstatus "1: Standby, 2: Park, 3: Driving";
CM_ SG_ 258 mcu_sportmode "1: sport, 0:eco";
CM_ SG_ 258 mcu_sidestand_sig "1: active, 0:inactive";
CM_ SG_ 295 scu_block_vehicle_sig "Vehicle block state:
0: unblock
1: blocked";
CM_ SG_ 295 scu_fail_dcdc_enable "Faildem signal for DCDC&MCU enable:
0: OK
1:NG";
CM_ SG_ 386 scu_Time_Format "Format of time on HMI:
- 0: 24h format
- 1: 12h format ";
CM_ SG_ 268 scu_scu_model "2 bytes. Evo 200-P1 show 0x50 0x31. Evo 200 Lite-P2 show 0x50 0x32";
CM_ SG_ 267 scu_turnleftlight_hmi "Signal turnleft light to HMI blink  led turnleft in 350ms";
CM_ SG_ 267 scu_displayspeedunit_hmi "1:m/h, 0: km/h";
CM_ SG_ 514 motorcontrol_check_scu_model "0: Correct scu_model
1: Lost scu_model during running
2: scu_model changed during running
3: Not received scu_model
4: Not match scu_model and mcu type ";
CM_ BO_ 782 "Status of battery pack.";
CM_ SG_ 782 bms_statusAdcPackVolt "Min) Sum of all series cell voltage.";
CM_ SG_ 782 bms_statusAdcAfterFuseVolt "Min) Sum of all series cell voltage.";
CM_ SG_ 782 bms_statusAdcAfterContactorVolt "Min) Sum of all series cell voltage.";
CM_ BO_ 795 "Cell voltage.";
CM_ SG_ 795 bms_statusVoltageCell22 "Min) Cell voltage.";
CM_ SG_ 795 bms_statusVoltageCell21 "Min) Cell voltage.";
CM_ BO_ 794 "Cell voltage.";
CM_ SG_ 794 bms_statusVoltageCell20 "Min) Cell voltage.";
CM_ SG_ 794 bms_statusVoltageCell19 "Min) Cell voltage.";
CM_ SG_ 794 bms_statusVoltageCell18 "Min) Cell voltage.";
CM_ SG_ 794 bms_statusVoltageCell17 "Min) Cell voltage.";
CM_ BO_ 257 "0,1,2,3,0,1,2,3. it counts if all of the processes in the microcontroller are working properly.  It should stop counting if a process gets stuck";
CM_ SG_ 257 scu_statusRollingCounter "0,1,2,3,0,1,2,3. it counts if all of the processes in the microcontroller are working properly.  It should stop counting if a process gets stuck";
CM_ SG_ 257 scu_commrequired_chg "1: start sending periodic CAN
0: stop sending periodic CAN";
CM_ BO_ 271 "-";
CM_ BO_ 272 "CBOX BMS Mode Command";
CM_ SG_ 272 scu_controlTBD1 "TBD";
CM_ SG_ 272 scu_statustrust_bms1 "None            (0)";
CM_ SG_ 272 scu_statustrust_bms0 "None            (0)";
CM_ SG_ 272 scu_statustrust_bms3 "None            (0)";
CM_ SG_ 272 scu_statustrust_bms2 "None            (0)";
CM_ SG_ 272 scu_resulttrust_bms1 "Trust Result";
CM_ SG_ 272 scu_resulttrust_bms0 "Trust Result";
CM_ SG_ 272 scu_resulttrust_bms3 "Trust Result";
CM_ SG_ 272 scu_resulttrust_bms2 "Trust Result";
CM_ SG_ 272 scu_controloffpfet_bms "Cbox Control BMS Pfet in sleep mode";
CM_ SG_ 272 scu_control_BMS_shutdown "Signal for VCU to shutdown BMS:
0: Normal
1: Shutdown";
CM_ BO_ 2 "Message use for ISO15765 of  BLG";
CM_ SG_ 2 bms_iso_signal "Signal use for ISO15765 of BMS0";
CM_ BO_ 513 "Total ODO of MCU to ( Unit: 100m)";
CM_ SG_ 513 mcu_speedkmh "Speed of motor control in rpm";
CM_ SG_ 513 mcu_totalODO "Total ODO of MCU to ( Unit: 100m)";
CM_ SG_ 513 mcu_brakesignal "0: Not active";
CM_ BO_ 768 "This message is used by the battery to control the system.";
CM_ SG_ 768 bms_controlSysMaxChgCurrent "sum) System Available max charging current value.";
CM_ SG_ 768 bms_controlSysMaxDsgCurrent "sum) System Available max discharging current value.";
CM_ SG_ 768 bms_controlSysMaxChgPower "sum) System Available max charging power value.";
CM_ SG_ 768 bms_controlSysMaxDsgPower "sum) System Available max discharging power value.";
CM_ BO_ 769 "Status of Chariging status";
CM_ SG_ 769 bms_chargingVoltageLimit "Min) Voltage limitation value for charging (in case of fault, this value will be zero)";
CM_ SG_ 769 bms_chargingCurrentLimit "Min) Current limitation value for charging (in case of fault, this value will be zero)";
CM_ SG_ 769 bms_chargingFullyChargedSts "Or) Fully charged status. ";
CM_ SG_ 769 bms_controlModeCharger "0: BMS control Charge OFFF
1: BMS control Charge normal
2: BMS Control charge in Trickle mode";
CM_ SG_ 769 bms_endCurrentCharge "BMS send end charge current to charger stop charge";
CM_ SG_ 769 bms_trickleCurrentCharger "BMS send max Trickle current to limit current in Trickle mode";
CM_ SG_ 769 bms_chargingDiagCharger "Or) DiagCharger";
CM_ BO_ 771 "Status of BMS.";
CM_ SG_ 771 bms_wakeupSource "Wakeup source of BMS:
1: HW switch
0: Self wake by RTC";
CM_ SG_ 771 bms_statusIgnitionRecognition "And) Status that BMS recognizes ignition pin";
CM_ SG_ 771 bms_statusRollingCounter "Master) 0,1,2,3 -> 0,1,2,3.   It is rolling count means to BMS processing is well.  It will stop counting, if BMS processing gets stuck";
CM_ SG_ 771 bms_statusBmsUserMode "Sel) User mode of the battery pack.";
CM_ SG_ 771 bms_statusBmsOpState "Sel) Operation mode of the battery pack.";
CM_ SG_ 771 bms_statusCurrentDirection "Sel) Current(Amps) Direction";
CM_ SG_ 771 bms_stsDiagCellTopPriorResult "Max) Most Severe Cell Diagnosis Result based on priority of diagnosis item and diagnosis level.";
CM_ SG_ 771 bms_stsRentalFuncEnable "And) Rental Function Enable";
CM_ SG_ 771 bms_stsAuthFuncEnable "And) Authentication Function Enable";
CM_ BO_ 772 "Operating state of the cell balancing circuit of the battery pack.";
CM_ SG_ 772 bms_statusCB12 "Or) Status of cell balancing circuit.";
CM_ SG_ 772 bms_statusCB11 "Or) Status of cell balancing circuit.";
CM_ SG_ 772 bms_statusCB10 "Or) Status of cell balancing circuit.";
CM_ SG_ 772 bms_statusCB09 "Or) Status of cell balancing circuit.";
CM_ SG_ 772 bms_statusCB02 "Or) Status of cell balancing circuit.";
CM_ SG_ 772 bms_statusCB01 "Or) Status of cell balancing circuit.";
CM_ SG_ 772 bms_statusCB04 "Or) Status of cell balancing circuit.";
CM_ SG_ 772 bms_statusCB03 "Or) Status of cell balancing circuit.";
CM_ SG_ 772 bms_statusCB06 "Or) Status of cell balancing circuit.";
CM_ SG_ 772 bms_statusCB05 "Or) Status of cell balancing circuit.";
CM_ SG_ 772 bms_statusCB08 "Or) Status of cell balancing circuit.";
CM_ SG_ 772 bms_statusCB07 "Or) Status of cell balancing circuit.";
CM_ BO_ 773 "Operating state of the cell balancing circuit of the battery pack.";
CM_ SG_ 773 bms_statusCB22 "Or) Status of cell balancing circuit.";
CM_ SG_ 773 bms_statusCB21 "Or) Status of cell balancing circuit.";
CM_ SG_ 773 bms_statusCB20 "Or) Status of cell balancing circuit.";
CM_ SG_ 773 bms_statusCB19 "Or) Status of cell balancing circuit.";
CM_ SG_ 773 bms_statusCB18 "Or) Status of cell balancing circuit.";
CM_ SG_ 773 bms_statusCB17 "Or) Status of cell balancing circuit.";
CM_ SG_ 773 bms_statusCB16 "Or) Status of cell balancing circuit.";
CM_ SG_ 773 bms_statusCB15 "Or) Status of cell balancing circuit.";
CM_ SG_ 773 bms_statusCB14 "Or) Status of cell balancing circuit.";
CM_ SG_ 773 bms_statusCB13 "Or) Status of cell balancing circuit.";
CM_ BO_ 774 "Diagnostic information of the Cell.";
CM_ SG_ 774 bms_demOverVoltageCell "Max) Diagnosis - Over voltage Cell.";
CM_ SG_ 774 bms_demOverVoltagePack "Max) Diagnosis - Over voltage Pack.";
CM_ SG_ 774 bms_demUnderVoltageCell "Max) Diagnosis - Under voltage Cell.";
CM_ SG_ 774 bms_demUnderVoltagePack "Max) Diagnosis - Under voltage Pack.";
CM_ SG_ 774 bms_demOverCurrentChg "Max) Diagnosis - Over charge current.";
CM_ SG_ 774 bms_demOverCurrentDis "Max) Diagnosis - Over discharge current.";
CM_ SG_ 774 bms_demOverTemperatureChg "Max) Diagnosis - Over temperature in charging.";
CM_ SG_ 774 bms_demOverTemperatureDis "Max) Diagnosis - Over temperature in discharging.";
CM_ SG_ 774 bms_demUnderTemperatureChg "Max) Diagnosis - Under temperature in charging.";
CM_ SG_ 774 bms_demUnderTemperatureDis "Max) Diagnosis - Under temperature in discharging.";
CM_ SG_ 774 bms_demImbCellChg "Max) Diagnosis - Cell voltage imbalance in Charging.";
CM_ SG_ 774 bms_demImbCellRest "Max) Diagnosis - Cell voltage imbalance in Rest.";
CM_ SG_ 774 bms_demImbCellTemperature "Max) Diagnosis - Imbalance Cell Temperature";
CM_ SG_ 774 bms_demImbCellSOC "Max) Diagnosis - Cell SOC imbalance.";
CM_ BO_ 775 "Diagnostic information of the Cell.";
CM_ SG_ 775 bms_demOverVoltageCellCount "Max) Diagnosis - Over voltage Cell Fault Count. If count reach to maximum value, it is sustained, no overflow.";
CM_ SG_ 775 bms_demUnderVoltageCellCount "Max) Diagnosis - Under voltage Cell Fault Count. If count reach to maximum value, it is sustained, no overflow.";
CM_ SG_ 775 bms_demOverCurrentChgCount "Max) Diagnosis - Over charge current Fault Count. If count reach to maximum value, it is sustained, no overflow.";
CM_ SG_ 775 bms_demOverCurrentDisCount "Max) Diagnosis - Over discharge current Fault Count. If count reach to maximum value, it is sustained, no overflow.";
CM_ SG_ 775 bms_demOverTemperatureChgCount "Max) Diagnosis - Over temperature in charging Fault Count. If count reaches maximum value, it is sustained, no overflow.";
CM_ SG_ 775 bms_demUnderTemperatureChgCount "Max) Diagnosis - Under temperature in charging Fault Count. If count reach to maximum value, it is sustained, no overflow.";
CM_ SG_ 775 bms_demOverTemperatureDisCount "Max) Diagnosis - Over temperature in discharging Fault Count. If count reach to maximum value, it is sustained, no overflow.";
CM_ SG_ 775 bms_demUnderTemperatureDisCount "Max) Diagnosis - Under temperature in discharging Fault Count. If count reach to maximum value, it is sustained, no overflow.";
CM_ BO_ 776 "Diagnostic information of the Cell.";
CM_ SG_ 776 bms_demImbCellChgCount "Max) Diagnosis - Cell voltage imbalance in Charging Fault Count. If count reach to maximum value, it is sustained, no overflow.";
CM_ SG_ 776 bms_demImbCellRestCount "Max) Diagnosis - Cell voltage imbalance in Rest Fault Count. If count reach to maximum value, it is sustained, no overflow.";
CM_ SG_ 776 bms_demImbCellTemperatureCount "Max) Diagnosis - Cell Temperature imbalance Fault Count. If count reach to maximum value, it is sustained, no overflow.";
CM_ SG_ 776 bms_demOverVoltagePackCount "Max) Diagnosis - Over voltage Pack Fault Count. If count reach to maximum value, it is sustained, no overflow.";
CM_ SG_ 776 bms_demUnderVoltagePackCount "Max) Diagnosis - Under voltage Pack Fault Count. If count reach to maximum value, it is sustained, no overflow.";
CM_ SG_ 776 bms_demImbCellSOCCount "Max) Diagnosis - Cell SOC imbalance Fault Count. If count reach to maximum value, it is sustained, no overflow. ";
CM_ BO_ 777 "Status of battery pack.";
CM_ SG_ 777 bms_statusPowerHSD "And) control status of C-FET";
CM_ SG_ 777 bms_statusPowerLSD "And) control status of D-FET";
CM_ SG_ 777 bms_statusLowCapacityAlarm "Or) Alarm - Low capacity (SOC < 10%)";
CM_ SG_ 777 bms_statusPrechargeFET "And) control status of Precharge-FET";
CM_ SG_ 777 bms_statusPackVoltageBAT "Min) Sum of all series cell voltage.";
CM_ SG_ 777 bms_statusTBD1 "Sum) TBD";
CM_ SG_ 777 bms_statusPackCurrent "Sum) Measuring pack current,  charging is positive, discharging is negative.";
CM_ BO_ 778 "SOH, RSOC, Cycle count, ... of battery pack.";
CM_ SG_ 778 bms_socFullChargeCapacityAh "Sum) Full Charge Capacity Ah.";
CM_ SG_ 778 bms_socRemainingCapacityAh "Sum) Remaining Capacity Ah.";
CM_ SG_ 778 bms_socRSOC "Min) Relative State Of Charge.";
CM_ SG_ 778 bms_socSOH "Min) State of health.";
CM_ SG_ 778 bms_socCycleCount "Max) Cycle Count";
CM_ SG_ 778 bms_socRemainingChargingTime "Min) Remaining Charging Time";
CM_ BO_ 779 "Accumulated Discharge/Charge Capacity";
CM_ SG_ 779 bms_AccumChargeCapacityAh "Max) Accumulated Charge Capacity(Ah)";
CM_ SG_ 779 bms_AccumDischargeCapacityAh "Max) Accumulated Discharge Capacity(Ah)";
CM_ BO_ 780 "Diagnostic information of the Aisc.";
CM_ SG_ 780 bms_demAsicOverVoltage "Max) Diagnosis - Asic Over Voltage";
CM_ SG_ 780 bms_demAsicUnderVoltage "Max) Diagnosis - Asic Under Voltage";
CM_ SG_ 780 bms_demAsicOverCurrentDis "Max) Diagnosis - Asic Discharge Over Current";
CM_ SG_ 780 bms_demAsicShortCurrent "Max) Diagnosis - Asic Short Current";
CM_ SG_ 780 bms_demAsicDeviceXReady "Max) Diagnosis - Asic Device X Ready";
CM_ SG_ 780 bms_demAsicOverRide "Max) Diagnosis - Asic Over Ride";
CM_ BO_ 781 "Diagnostic information of the Aisc.";
CM_ SG_ 781 bms_demAsicOverVoltageCount "Max) Diagnosis - Asic Over Voltage Occurred Count. If count reach to maximum value, it is sustained, no overflow.";
CM_ SG_ 781 bms_demAsicUnderVoltageCount "Max) Diagnosis - Asic Under Voltage Occurred Count. If count reach to maximum value, it is sustained, no overflow.";
CM_ SG_ 781 bms_demAsicOverCurrentDisCount "Max) Diagnosis - Asic Discharge Over Current Occurred Count. If count reach to maximum value, it is sustained, no overflow.";
CM_ SG_ 781 bms_demAsicShortCurrentCount "Max) Diagnosis - Asic Short Current Occured Count. If count reach to maximum value, it is sustained, no overflow.";
CM_ SG_ 781 bms_demAsicDeviceXReadyCount "Max) Diagnosis - Asic Device X Ready Occurred Count";
CM_ SG_ 781 bms_demAsicOverRideCount "Max) Diagnosis - Asic Over Ride Occurred Count. If count reach to maximum value, it is sustained, no overflow.";
CM_ BO_ 784 "Cell voltage.";
CM_ SG_ 784 bms_statusVoltageCellAvg "Min) Average cell voltage.";
CM_ SG_ 784 bms_statusVoltageCellMin "Min) minimum cell voltage.";
CM_ SG_ 784 bms_statusVoltageCellMinNo "Sel) minimum cell voltage number";
CM_ SG_ 784 bms_statusVoltageCellMax "Max) maximum cell voltage.";
CM_ SG_ 784 bms_statusVoltageCellMaxNo "Sel) maximum cell voltage number";
CM_ BO_ 785 "Cell voltage.";
CM_ SG_ 785 bms_statusVoltageCell01 "Min) Cell voltage.";
CM_ SG_ 785 bms_statusVoltageCell02 "Min) Cell voltage.";
CM_ SG_ 785 bms_statusVoltageCell03 "Min) Cell voltage.";
CM_ SG_ 785 bms_statusVoltageCell04 "Min) Cell voltage.";
CM_ BO_ 786 "Cell voltage.";
CM_ SG_ 786 bms_statusVoltageCell05 "Min) Cell voltage.";
CM_ SG_ 786 bms_statusVoltageCell06 "Min) Cell voltage.";
CM_ SG_ 786 bms_statusVoltageCell07 "Min) Cell voltage.";
CM_ SG_ 786 bms_statusVoltageCell08 "Min) Cell voltage.";
CM_ BO_ 787 "Cell voltage.";
CM_ SG_ 787 bms_statusVoltageCell09 "Min) Cell voltage.";
CM_ SG_ 787 bms_statusVoltageCell10 "Min) Cell voltage.";
CM_ SG_ 787 bms_statusVoltageCell11 "Min) Cell voltage.";
CM_ SG_ 787 bms_statusVoltageCell12 "Min) Cell voltage.";
CM_ BO_ 788 "Cell voltage.";
CM_ SG_ 788 bms_statusVoltageCell16 "Min) Cell voltage.";
CM_ SG_ 788 bms_statusVoltageCell15 "Min) Cell voltage.";
CM_ SG_ 788 bms_statusVoltageCell13 "Min) Cell voltage.";
CM_ SG_ 788 bms_statusVoltageCell14 "Min) Cell voltage.";
CM_ BO_ 789 "Diagnostic information of the BMS.";
CM_ SG_ 789 bms_demBMSCFET "Max) Diagnosis - BMS CFET";
CM_ SG_ 789 bms_demBMSDFET "Max) Diagnosis - BMS DFET";
CM_ SG_ 789 bms_demBMSPFET "Max) Diagnosis - BMS PFET";
CM_ SG_ 789 bms_demBMSASICComm "Max) Diagnosis - BMS ASIC Comm";
CM_ SG_ 789 bms_demBMSASICShutdown "Max) Diagnosis - BMS ASIC Shutdowm";
CM_ SG_ 789 bms_demBMSPFET2 "Max) Diagnosis - BMS PFET2 ( for External Short )";
CM_ BO_ 790 "Diagnostic information of the BMS.";
CM_ SG_ 790 bms_demBMSCFETCount "Max) Diagnosis - BMS CFET  Occurred Count. If count reach to maximum value, it is sustained, no overflow.";
CM_ SG_ 790 bms_demBMSDFETCount "Max) Diagnosis - BMS DFET Occurred Count. If count reach to maximum value, it is sustained, no overflow.";
CM_ SG_ 790 bms_demBMSPFETCount "Max) Diagnosis - BMS PFET Occurred Count. If count reach to maximum value, it is sustained, no overflow.";
CM_ SG_ 790 bms_demBMSASICCommCount "Max) Diagnosis - BMS ASIC Comm Occurred Count. If count reach to maximum value, it is sustained, no overflow.";
CM_ SG_ 790 bms_demBMSASICShutdownCount "Max) Diagnosis - BMS ASIC Shutdown Occurred Count. If count reach to maximum value, it is sustained, no overflow.";
CM_ SG_ 790 bms_demBMSPFET2Count "Max) Diagnosis - BMS PFET2 Occurred Count. If count reach to maximum value, it is sustained, no overflow.";
CM_ BO_ 791 "Diagnostic information of the Pack.";
CM_ SG_ 791 bms_demConStuckOpen "Max) Diagnosis - Pack Fuse Blow";
CM_ SG_ 791 bms_demConStuckClosed "Max) Diagnosis - Pack Fuse Blow";
CM_ SG_ 791 bms_demPackFuseBlow "Max) Diagnosis - Pack Fuse Blow";
CM_ SG_ 791 bms_demPackFuseResistance "Max) Diagnosis - Pack Fuse Resistance Current";
CM_ SG_ 791 bms_demPackFuseOverCurrent "Max) Diagnosis - Pack Fuse Over Current";
CM_ SG_ 791 bms_demPackFETTemperature "Max) Diagnosis - Pack FET Temperature(Over)";
CM_ BO_ 792 "Diagnostic information of the Pack.";
CM_ SG_ 792 bms_demConStuckOpenCount "Max) Diagnosis - Cell voltage imbalance in Charging Fault Count. If count reach to maximum value, it is sustained, no overflow.";
CM_ SG_ 792 bms_demConStuckClosedCount "Max) Diagnosis - Cell voltage imbalance in Charging Fault Count. If count reach to maximum value, it is sustained, no overflow.";
CM_ SG_ 792 bms_demPackFuseBlowCount "Max) Diagnosis - Pack Fuse Blow Occurred Count. If count reach to maximum value, it is sustained, no overflow.";
CM_ SG_ 792 bms_demPackFuseResistanceCount "Max) Diagnosis - Pack Fuse Resistance Current Occurred Count";
CM_ SG_ 792 bms_demPackFuseOverCurrentCount "Max) Diagnosis - Pack Fuse Over Current Occurred Count. If count reach to maximum value, it is sustained, no overflow.";
CM_ SG_ 792 bms_demPackFETTemperatureCount "Max) Diagnosis - Pack FET Temperature(Over) Occurred Count. If count reach to maximum value, it is sustained, no overflow.";
CM_ BO_ 793 "Pack life time mileage data";
CM_ SG_ 793 bms_mileage_data "Max) Pack life time mileage data";
CM_ SG_ 793 bms_mileageTBD1 "Max) TBD";
CM_ BO_ 800 "Cell temperature inside the battery pack.";
CM_ SG_ 800 bms_statusTemperatureCellAvg "Avg) Average Temperature - cell.";
CM_ SG_ 800 bms_statusTemperatureCellMin "Min) Minimum Temperature - cell.";
CM_ SG_ 800 bms_statusTemperatureCellMinNo "Sel) Minimum Temperature Number - cell.";
CM_ SG_ 800 bms_statusTemperatureCellMax "Max) Maximum Temperature - cell.";
CM_ SG_ 800 bms_statusTemperatureCellMaxNo "Sel) Maximum Temperature Number - cell.";
CM_ BO_ 801 "Cell temperature inside the battery pack.";
CM_ SG_ 801 bms_statusTemperatureCell4 "Max) Temperature - cell.";
CM_ SG_ 801 bms_statusTemperatureCell1 "Max) Temperature - cell.";
CM_ SG_ 801 bms_statusTemperatureCell2 "Max) Temperature - cell.";
CM_ SG_ 801 bms_statusTemperatureCell3 "Max) Temperature - cell.";
CM_ BO_ 802 "Temperature of the components in the battery pack.";
CM_ SG_ 802 bms_statusTemperatureCB4 "Max) Temperature - cell balancing circuit.";
CM_ SG_ 802 bms_statusTemperatureCB3 "Max) Temperature - cell balancing circuit.";
CM_ SG_ 802 bms_statusTemperatureCB1 "Max) Temperature - cell balancing circuit.";
CM_ SG_ 802 bms_statusTemperatureCB2 "Max) Temperature - cell balancing circuit.";
CM_ BO_ 803 "-";
CM_ SG_ 803 bms_rentalinfo_remaintime "Min) Rental Remain Time";
CM_ SG_ 803 bms_rentalinfo_bonustime "Min) Bonus Charge";
CM_ SG_ 803 bms_rentalinfo_expired "Or) Rental Expired";
CM_ SG_ 803 bms_rentalinfoTBD1 "Min) TBD";
CM_ SG_ 803 bms_rentalinfoTBD2 "Min) TBD";
CM_ BO_ 804 "Customer ID: 8 low bytes";
CM_ SG_ 804 bms_rentalinfo_customer1 "Sel) CustomerID1";
CM_ SG_ 804 bms_rentalinfo_customer12 "Sel) CustomerID2";
CM_ BO_ 805 "Customer ID: 8 high bytes";
CM_ SG_ 805 bms_rentalinfo_customer2 "Sel) CustomerID3";
CM_ SG_ 805 bms_rentalinfo_customer22 "Sel) CustomerID4";
CM_ BO_ 806 "TrustInfo";
CM_ SG_ 806 bms_statustrust_bms1charger "Sel) Trust Status";
CM_ SG_ 806 bms_statustrust_bms0charger "Sel) Trust Status";
CM_ SG_ 806 bms_statustrust_bms3charger "Sel) Trust Status";
CM_ SG_ 806 bms_statustrust_bms2charger "Sel) Trust Status";
CM_ SG_ 806 bms_resulttrust_bms1charger "Sel) Trust Result";
CM_ SG_ 806 bms_resulttrust_bms0charger "Sel) Trust Result";
CM_ SG_ 806 bms_resulttrust_bms3charger "Sel) Trust Result";
CM_ SG_ 806 bms_resulttrust_bms2charger "Sel) Trust Result";
CM_ SG_ 806 bms_statustrust_bms1cbox "Sel) Trust Status : Master BMS BMS2VHC Fail Flag Status for sharing to slave";
CM_ SG_ 806 bms_statustrust_bms0cbox "Sel) Trust Status : Master BMS BMS2VHC Fail Flag Status for sharing to slave";
CM_ SG_ 806 bms_statustrust_bms3cbox "Sel) Trust Status";
CM_ SG_ 806 bms_statustrust_bms2cbox "Sel) Trust Status";
CM_ SG_ 806 bms_resulttrust_bms1cbox "Sel) Trust Result";
CM_ SG_ 806 bms_resulttrust_bms0cbox "Sel) Trust Result";
CM_ SG_ 806 bms_resulttrust_bms3cbox "Sel) Trust Result";
CM_ SG_ 806 bms_resulttrust_bms2cbox "Sel) Trust Result";
CM_ BO_ 807 "Parallel Diagnosis";
CM_ SG_ 807 bms_demParallelOvrdSlave "Max) Diagnosis - Parallel Overide Slave";
CM_ SG_ 807 bms_demParallelOvrdMaster "Max) Diagnosis - Parallel Overide Master";
CM_ SG_ 807 bms_demParallelDiffVoltage "Max) Diagnosis - Parallel Diff Voltage";
CM_ SG_ 807 bms_demParallelDiffCurrent "Max) Diagnosis - Parallel Diff Current";
CM_ SG_ 807 bms_demParallelDiffSOC "Max) Diagnosis - Parallel Diff SOC";
CM_ SG_ 807 bms_demParallelDiffTemp "Max) Diagnosis - Parallel Diff Temp";
CM_ SG_ 807 bms_demParallelDiffVer "Max) Diagnosis - Parallel Diff Ver";
CM_ SG_ 807 bms_demParallelDiffSOH "Max) Diagnosis - Parallel Diff SOH";
CM_ BO_ 816 "Parallel Satus";
CM_ SG_ 816 bms_statusID "Master) ID";
CM_ SG_ 816 bms_statusISOTPID "Master) ISOTP ID";
CM_ SG_ 816 bms_statusPackTimeout "BitOr) (bit field) Pack Timeout. Pack0,1,2,3";
CM_ SG_ 816 bms_statusMasterAuthSync "Or) Master Auth Sync";
CM_ SG_ 816 bms_statusParallelTBD1 "Sync) Diag Msater";
CM_ SG_ 816 bms_statusParallelDiagPack1 "Sel) Diag Pack1";
CM_ SG_ 816 bms_statusParallelDiagPack0 "Sel) Diag Pack0";
CM_ BO_ 831 "Version of battery pack or product information";
CM_ SG_ 831 bms_versionSoftwareMinor "Min) Version - application_minor";
CM_ SG_ 831 bms_versionSoftwareSubminor "Min) Version - application_subminor";
CM_ SG_ 831 bms_versionBootloaderMajor "Min) Version - bootloader";
CM_ SG_ 831 bms_versionSoftwareMajor "Min) Version - application_major";
CM_ SG_ 831 bms_versionBootloaderMinor "Min) Version - bootloader";
CM_ SG_ 831 bms_versionBootloaderSubminor "Min) Version - bootloader";
CM_ SG_ 831 bms_versionHardwareMajor "Min) Version - BMS HW";
CM_ SG_ 831 bms_versionTBD1 "Sync) TBD";
CM_ SG_ 831 bms_versionManufacturerDate "Min) Manufactuer Date";
CM_ SG_ 831 bms_versionManufacturerSerialNo "Min) manufacturer serial number per day";
CM_ BO_ 1281 "0,1,2,3,0,1,2,3.   it counts if all of the processes in the microcontroller are working properly.  It should stop counting if a process gets stuck";
CM_ SG_ 1281 charger_rollingcounter "0,1,2,3,0,1,2,3.   it counts if all of the processes in the microcontroller are working properly.  It should stop counting if a process gets stuck";
CM_ BO_ 1282 "None            (0)";
CM_ SG_ 1282 charger_type "Define charger type:";
CM_ SG_ 1282 charger_statustrust_bms0 "Trust Result";
CM_ SG_ 1282 charger_statustrust_bms3 "Trust Result";
CM_ SG_ 1282 charger_statustrust_bms2 "Trust Result";
CM_ SG_ 1282 charger_resulttrust_bms1 "Trust Result";
CM_ SG_ 1282 charger_resulttrust_bms0 "Trust Result";
CM_ SG_ 1282 charger_resulttrust_bms3 "Trust Result";
CM_ SG_ 1282 charger_resulttrust_bms2 "Trust Result";
CM_ SG_ 1282 charger_commrequiredTBD1 "TBD";
CM_ BO_ 1283 "-";
CM_ BO_ 6 "MEssage use for ISO15765 of Cbox";
CM_ SG_ 6 scu_iso_signal "Signal use for ISO15765 of ECU";
CM_ BO_ 9 "Message use for ISO15765 of charger";
CM_ SG_ 9 charger_iso_signal "Signal use for ISO15765 of charger";
CM_ BO_ 1762 "-";
CM_ SG_ 1762 frpReqIndex_bms "Boot and Manufactuer Signal of LGC BMS";
CM_ SG_ 1762 frpReqSubIndex_bms "Boot and Manufactuer Signal of LGC BMS";
CM_ SG_ 1762 frpReqData1_bms "Boot and Manufactuer Signal of LGC BMS";
CM_ SG_ 1762 frpReqData2_bms "Boot and Manufactuer Signal of LGC BMS";
CM_ SG_ 1762 frpReqData3_bms "Boot and Manufactuer Signal of LGC BMS";
CM_ SG_ 1762 frpReqData4_bms "Boot and Manufactuer Signal of LGC BMS";
CM_ SG_ 1762 frpReqData5_bms "Boot and Manufactuer Signal of LGC BMS";
CM_ BO_ 1777 "-";
CM_ SG_ 1777 frpReqIndex_FRP "Boot and Manufactuer Signal of LGC BMS";
CM_ SG_ 1777 frpReqSubIndex_FRP "Boot and Manufactuer Signal of LGC BMS";
CM_ SG_ 1777 frpReqData1_FRP "Boot and Manufactuer Signal of LGC BMS";
CM_ SG_ 1777 frpReqData2_FRP "Boot and Manufactuer Signal of LGC BMS";
CM_ SG_ 1777 frpReqData3_FRP "Boot and Manufactuer Signal of LGC BMS";
CM_ SG_ 1777 frpReqData4_FRP "Boot and Manufactuer Signal of LGC BMS";
CM_ SG_ 1777 frpReqData5_FRP "Boot and Manufactuer Signal of LGC BMS";
BA_DEF_  "BusECUIdLength" INT 5 6;
BA_DEF_  "BusID" INT 0 255;
BA_DEF_  "BusName" STRING ;
BA_DEF_  "BusType" STRING ;
BA_DEF_  "DBName" STRING ;
BA_DEF_ BO_  "cycleMilliSecs100" INT 0 100;
BA_DEF_ BO_  "GenMsgCycleTime" INT 0 65000;
BA_DEF_ BO_  "GenMsgSendType" ENUM  "Fixed Periodic","Enabled Periodic","NoMsgSendType","Event";
BA_DEF_ BO_  "targetGw" ENUM  "BPG","BGW","IVI","SDCM","ALL";
BA_DEF_ BO_  "transmitMsgRateEthernetMs" ENUM  "10","100","1000";
BA_DEF_ BU_  "NmDefaultAddress" ENUM  "USE_PRIMARY_ADDRESS","USE_SECONDARY_ADDRESS";
BA_DEF_ BU_  "NodeLayerModules" STRING ;
BA_DEF_ SG_  "SNARequired" ENUM  "Required","NotRequired";
BA_DEF_DEF_  "BusECUIdLength" 5;
BA_DEF_DEF_  "BusID" 0;
BA_DEF_DEF_  "BusName" "AuxBattery";
BA_DEF_DEF_  "BusType" "CAN";
BA_DEF_DEF_  "DBName" "";
BA_DEF_DEF_  "cycleMilliSecs100" 100;
BA_DEF_DEF_  "GenMsgCycleTime" 0;
BA_DEF_DEF_  "GenMsgSendType" "NoMsgSendType";
BA_DEF_DEF_  "targetGw" "ALL";
BA_DEF_DEF_  "transmitMsgRateEthernetMs" "1000";
BA_DEF_DEF_  "NmDefaultAddress" "USE_PRIMARY_ADDRESS";
BA_DEF_DEF_  "NodeLayerModules" "CANoeILNLVector.dll";
BA_DEF_DEF_  "SNARequired" "Required";
BA_ "BusName" "Battery";
BA_ "BusID" 136;
BA_ "DBName" "EV";
BA_ "GenMsgCycleTime" BO_ 262 500;
BA_ "GenMsgSendType" BO_ 262 0;
BA_ "GenMsgCycleTime" BO_ 258 150;
BA_ "GenMsgCycleTime" BO_ 256 1000;
BA_ "GenMsgSendType" BO_ 393 0;
BA_ "GenMsgCycleTime" BO_ 393 500;
BA_ "GenMsgSendType" BO_ 295 0;
BA_ "GenMsgCycleTime" BO_ 295 500;
BA_ "GenMsgSendType" BO_ 386 0;
BA_ "GenMsgCycleTime" BO_ 386 1000;
BA_ "GenMsgCycleTime" BO_ 268 250;
BA_ "GenMsgSendType" BO_ 268 0;
BA_ "GenMsgCycleTime" BO_ 267 150;
BA_ "GenMsgCycleTime" BO_ 261 1000;
BA_ "GenMsgCycleTime" BO_ 1024 1000;
BA_ "GenMsgCycleTime" BO_ 1026 500;
BA_ "GenMsgCycleTime" BO_ 512 1000;
BA_ "GenMsgCycleTime" BO_ 514 500;
BA_ "GenMsgSendType" BO_ 782 0;
BA_ "GenMsgCycleTime" BO_ 782 150;
BA_ "GenMsgSendType" BO_ 795 0;
BA_ "GenMsgCycleTime" BO_ 795 500;
BA_ "GenMsgSendType" BO_ 794 0;
BA_ "GenMsgCycleTime" BO_ 794 500;
BA_ "GenMsgCycleTime" BO_ 257 500;
BA_ "GenMsgSendType" BO_ 257 0;
BA_ "GenMsgCycleTime" BO_ 271 500;
BA_ "GenMsgSendType" BO_ 271 0;
BA_ "GenMsgCycleTime" BO_ 272 150;
BA_ "GenMsgSendType" BO_ 272 0;
BA_ "GenMsgCycleTime" BO_ 513 150;
BA_ "GenMsgSendType" BO_ 513 0;
BA_ "GenMsgCycleTime" BO_ 768 150;
BA_ "GenMsgSendType" BO_ 768 0;
BA_ "GenMsgCycleTime" BO_ 769 1000;
BA_ "GenMsgSendType" BO_ 769 0;
BA_ "GenMsgCycleTime" BO_ 771 150;
BA_ "GenMsgSendType" BO_ 771 0;
BA_ "GenMsgCycleTime" BO_ 772 1000;
BA_ "GenMsgSendType" BO_ 772 0;
BA_ "GenMsgCycleTime" BO_ 773 1000;
BA_ "GenMsgSendType" BO_ 773 0;
BA_ "GenMsgCycleTime" BO_ 774 150;
BA_ "GenMsgSendType" BO_ 774 0;
BA_ "GenMsgCycleTime" BO_ 775 5000;
BA_ "GenMsgSendType" BO_ 775 0;
BA_ "GenMsgCycleTime" BO_ 776 5000;
BA_ "GenMsgSendType" BO_ 776 0;
BA_ "GenMsgCycleTime" BO_ 777 150;
BA_ "GenMsgSendType" BO_ 777 0;
BA_ "GenMsgCycleTime" BO_ 778 1000;
BA_ "GenMsgSendType" BO_ 778 0;
BA_ "GenMsgCycleTime" BO_ 779 3000;
BA_ "GenMsgSendType" BO_ 779 0;
BA_ "GenMsgCycleTime" BO_ 780 500;
BA_ "GenMsgSendType" BO_ 780 0;
BA_ "GenMsgCycleTime" BO_ 781 5000;
BA_ "GenMsgSendType" BO_ 781 0;
BA_ "GenMsgCycleTime" BO_ 784 500;
BA_ "GenMsgSendType" BO_ 784 0;
BA_ "GenMsgCycleTime" BO_ 785 500;
BA_ "GenMsgSendType" BO_ 785 0;
BA_ "GenMsgCycleTime" BO_ 786 500;
BA_ "GenMsgSendType" BO_ 786 0;
BA_ "GenMsgCycleTime" BO_ 787 500;
BA_ "GenMsgSendType" BO_ 787 0;
BA_ "GenMsgCycleTime" BO_ 788 500;
BA_ "GenMsgSendType" BO_ 788 0;
BA_ "GenMsgCycleTime" BO_ 789 500;
BA_ "GenMsgSendType" BO_ 789 0;
BA_ "GenMsgCycleTime" BO_ 790 5000;
BA_ "GenMsgSendType" BO_ 790 0;
BA_ "GenMsgCycleTime" BO_ 791 500;
BA_ "GenMsgSendType" BO_ 791 0;
BA_ "GenMsgCycleTime" BO_ 792 5000;
BA_ "GenMsgSendType" BO_ 792 0;
BA_ "GenMsgCycleTime" BO_ 793 5000;
BA_ "GenMsgSendType" BO_ 793 0;
BA_ "GenMsgCycleTime" BO_ 800 1000;
BA_ "GenMsgSendType" BO_ 800 0;
BA_ "GenMsgCycleTime" BO_ 801 1000;
BA_ "GenMsgSendType" BO_ 801 0;
BA_ "GenMsgCycleTime" BO_ 802 500;
BA_ "GenMsgSendType" BO_ 802 0;
BA_ "GenMsgCycleTime" BO_ 803 3000;
BA_ "GenMsgSendType" BO_ 803 0;
BA_ "GenMsgCycleTime" BO_ 804 3000;
BA_ "GenMsgSendType" BO_ 804 0;
BA_ "GenMsgCycleTime" BO_ 805 3000;
BA_ "GenMsgSendType" BO_ 805 0;
BA_ "GenMsgCycleTime" BO_ 806 150;
BA_ "GenMsgSendType" BO_ 806 0;
BA_ "GenMsgCycleTime" BO_ 807 500;
BA_ "GenMsgSendType" BO_ 807 0;
BA_ "GenMsgCycleTime" BO_ 816 500;
BA_ "GenMsgSendType" BO_ 816 0;
BA_ "GenMsgCycleTime" BO_ 831 1000;
BA_ "GenMsgSendType" BO_ 831 0;
BA_ "GenMsgCycleTime" BO_ 1281 500;
BA_ "GenMsgSendType" BO_ 1281 0;
BA_ "GenMsgCycleTime" BO_ 1282 150;
BA_ "GenMsgSendType" BO_ 1282 0;
BA_ "GenMsgCycleTime" BO_ 1283 500;
BA_ "GenMsgSendType" BO_ 1283 0;
VAL_ 3221225472 scu_commrequired_scu 0 "Stop" 1 "Start" 2 "RSVD1" 3 "RSVD2" ;
VAL_ 268 scu_scu_model 20530 "P2-Evo 200 Lite" 20529 "P1-Evo 200" ;
VAL_ 514 motorcontrol_check_scu_model 4 "Not match scu_model and mcu type" 3 "Not received scu_model" 2 "scu_model changed during running" 1 "Lost scu_model during running" 0 "Correct scu_model" ;
VAL_ 257 scu_commrequired_mcu 0 "Stop" 1 "Start" 2 "RSVD1" 3 "RSVD2" ;
VAL_ 257 scu_commrequired_hmi 0 "Stop" 1 "Start" 2 "RSVD1" 3 "RSVD2" ;
VAL_ 257 scu_commrequired_bms 0 "Stop" 1 "Start" 2 "RSVD1" 3 "RSVD2" ;
VAL_ 271 scu_ignitionstatus_bms 0 "Low" 1 "High" ;
VAL_ 272 scu_controlmode_bms 0 "Go to Standby" 1 "Go to TrustVHC Mode" 2 "Go to TrustCHG Mode" 3 "Go to Working Mode" 4 "Go to Sleep Mode" 5 "Go to Shutdown Mode" 6 "Go to VF Setting Mode" ;
VAL_ 272 scu_statustrust_bms1 0 "READY" 1 "PASS" 2 "FAIL" 3 "PROCESSING" 4 "TIMEOUT" ;
VAL_ 272 scu_statustrust_bms0 0 "READY" 1 "PASS" 2 "FAIL" 3 "PROCESSING" 4 "TIMEOUT" ;
VAL_ 272 scu_statustrust_bms3 0 "READY" 1 "PASS" 2 "FAIL" 3 "PROCESSING" 4 "TIMEOUT" ;
VAL_ 272 scu_statustrust_bms2 0 "READY" 1 "PASS" 2 "FAIL" 3 "PROCESSING" 4 "TIMEOUT" ;
VAL_ 272 scu_resulttrust_bms1 0 "READY" 1 "PASS" 2 "FAIL" 3 "PROCESSING" 4 "TIMEOUT" ;
VAL_ 272 scu_resulttrust_bms0 0 "READY" 1 "PASS" 2 "FAIL" 3 "PROCESSING" 4 "TIMEOUT" ;
VAL_ 272 scu_resulttrust_bms3 0 "READY" 1 "PASS" 2 "FAIL" 3 "PROCESSING" 4 "TIMEOUT" ;
VAL_ 272 scu_resulttrust_bms2 0 "READY" 1 "PASS" 2 "FAIL" 3 "PROCESSING" 4 "TIMEOUT" ;
VAL_ 272 scu_controloffpfet_bms 0 "ON" 1 "OFF" ;
VAL_ 769 bms_chargingFullyChargedSts 0 "N/A" 1 "Charging" 2 "Fully Charged" ;
VAL_ 771 bms_statusIgnitionRecognition 0 "Low" 1 "High" ;
VAL_ 771 bms_statusBmsUserMode 0 "Standby Mode" 1 "TrustVHC Mode" 2 "TrustCHG Mode" 3 "Working Mode" ;
VAL_ 771 bms_statusBmsOpState 0 "_OP_STATE_MFG" 1 "_OP_STATE_FAILURE" 2 "_OP_STATE_PACK" ;
VAL_ 771 bms_statusCurrentDirection 0 "Rest" 1 "Charging" 2 "Discharging" ;
VAL_ 771 bms_stsRentalFuncEnable 0 "Disable" 1 "Enable" ;
VAL_ 771 bms_stsAuthFuncEnable 0 "Disable" 1 "Enable" ;
VAL_ 772 bms_statusCB12 0 "Off" 1 "On" ;
VAL_ 772 bms_statusCB11 0 "Off" 1 "On" ;
VAL_ 772 bms_statusCB10 0 "Off" 1 "On" ;
VAL_ 772 bms_statusCB09 0 "Off" 1 "On" ;
VAL_ 772 bms_statusCB02 0 "Off" 1 "On" ;
VAL_ 772 bms_statusCB01 0 "Off" 1 "On" ;
VAL_ 772 bms_statusCB04 0 "Off" 1 "On" ;
VAL_ 772 bms_statusCB03 0 "Off" 1 "On" ;
VAL_ 772 bms_statusCB06 0 "Off" 1 "On" ;
VAL_ 772 bms_statusCB05 0 "Off" 1 "On" ;
VAL_ 772 bms_statusCB08 0 "Off" 1 "On" ;
VAL_ 772 bms_statusCB07 0 "Off" 1 "On" ;
VAL_ 773 bms_statusCB22 0 "Off" 1 "On" ;
VAL_ 773 bms_statusCB21 0 "Off" 1 "On" ;
VAL_ 773 bms_statusCB20 0 "Off" 1 "On" ;
VAL_ 773 bms_statusCB19 0 "Off" 1 "On" ;
VAL_ 773 bms_statusCB18 0 "Off" 1 "On" ;
VAL_ 773 bms_statusCB17 0 "Off" 1 "On" ;
VAL_ 773 bms_statusCB16 0 "Off" 1 "On" ;
VAL_ 773 bms_statusCB15 0 "Off" 1 "On" ;
VAL_ 773 bms_statusCB14 0 "Off" 1 "On" ;
VAL_ 773 bms_statusCB13 0 "Off" 1 "On" ;
VAL_ 774 bms_demOverVoltageCell 0 "Normal" 1 "Warning1" 2 "Warning2" 3 "Fault" 4 "Failure" 5 "RSVD5" 6 "RSVD6" 7 "RSVD7" ;
VAL_ 774 bms_demOverVoltagePack 0 "Normal" 1 "Warning1" 2 "Warning2" 3 "Fault" 4 "Failure" 5 "RSVD5" 6 "RSVD6" 7 "RSVD7" ;
VAL_ 774 bms_demUnderVoltageCell 0 "Normal" 1 "Warning1" 2 "Warning2" 3 "Fault" 4 "Failure" 5 "RSVD5" 6 "RSVD6" 7 "RSVD7" ;
VAL_ 774 bms_demUnderVoltagePack 0 "Normal" 1 "Warning1" 2 "Warning2" 3 "Fault" 4 "Failure" 5 "RSVD5" 6 "RSVD6" 7 "RSVD7" ;
VAL_ 774 bms_demOverCurrentChg 0 "Normal" 1 "Warning1" 2 "Warning2" 3 "Fault" 4 "Failure" 5 "RSVD5" 6 "RSVD6" 7 "RSVD7" ;
VAL_ 774 bms_demOverCurrentDis 0 "Normal" 1 "Warning1" 2 "Warning2" 3 "Fault" 4 "Failure" 5 "RSVD5" 6 "RSVD6" 7 "RSVD7" ;
VAL_ 774 bms_demOverTemperatureChg 0 "Normal" 1 "Warning1" 2 "Warning2" 3 "Fault" 4 "Failure" 5 "RSVD5" 6 "RSVD6" 7 "RSVD7" ;
VAL_ 774 bms_demOverTemperatureDis 0 "Normal" 1 "Warning1" 2 "Warning2" 3 "Fault" 4 "Failure" 5 "RSVD5" 6 "RSVD6" 7 "RSVD7" ;
VAL_ 774 bms_demUnderTemperatureChg 0 "Normal" 1 "Warning1" 2 "Warning2" 3 "Fault" 4 "Failure" 5 "RSVD5" 6 "RSVD6" 7 "RSVD7" ;
VAL_ 774 bms_demUnderTemperatureDis 0 "Normal" 1 "Warning1" 2 "Warning2" 3 "Fault" 4 "Failure" 5 "RSVD5" 6 "RSVD6" 7 "RSVD7" ;
VAL_ 774 bms_demImbCellChg 0 "Normal" 1 "Warning1" 2 "Warning2" 3 "Fault" 4 "Failure" 5 "RSVD5" 6 "RSVD6" 7 "RSVD7" ;
VAL_ 774 bms_demImbCellRest 0 "Normal" 1 "Warning1" 2 "Warning2" 3 "Fault" 4 "Failure" 5 "RSVD5" 6 "RSVD6" 7 "RSVD7" ;
VAL_ 774 bms_demImbCellTemperature 0 "Normal" 1 "Warning1" 2 "Warning2" 3 "Fault" 4 "Failure" 5 "RSVD5" 6 "RSVD6" 7 "RSVD7" ;
VAL_ 774 bms_demImbCellSOC 0 "Normal" 1 "Warning1" 2 "Warning2" 3 "Fault" 4 "Failure" 5 "RSVD5" 6 "RSVD6" 7 "RSVD7" ;
VAL_ 777 bms_statusPowerHSD 0 "Off" 1 "On" 2 "RSVD1" 3 "RSVD2" ;
VAL_ 777 bms_statusPowerLSD 0 "Off" 1 "On" 2 "RSVD1" 3 "RSVD2" ;
VAL_ 777 bms_statusLowCapacityAlarm 0 "Clear" 1 "Set" 2 "RSVD1" 3 "RSVD2" ;
VAL_ 777 bms_statusPrechargeFET 0 "Off" 1 "On" 2 "RSVD1" 3 "RSVD2" ;
VAL_ 780 bms_demAsicOverVoltage 0 "Normal" 3 "Fault" ;
VAL_ 780 bms_demAsicUnderVoltage 0 "Normal" 3 "Fault" ;
VAL_ 780 bms_demAsicOverCurrentDis 0 "Normal" 3 "Fault" ;
VAL_ 780 bms_demAsicShortCurrent 0 "Normal" 3 "Fault" ;
VAL_ 780 bms_demAsicDeviceXReady 0 "Normal" 3 "Fault" ;
VAL_ 780 bms_demAsicOverRide 0 "Normal" 3 "Fault" ;
VAL_ 789 bms_demBMSCFET 0 "Normal" 3 "Fault" ;
VAL_ 789 bms_demBMSDFET 0 "Normal" 3 "Fault" ;
VAL_ 789 bms_demBMSPFET 0 "Normal" 3 "Fault" ;
VAL_ 789 bms_demBMSASICComm 0 "Normal" 3 "Fault" ;
VAL_ 789 bms_demBMSASICShutdown 0 "Normal" 3 "Fault" ;
VAL_ 789 bms_demBMSPFET2 0 "Normal" 3 "Fault" ;
VAL_ 791 bms_demConStuckOpen 1 "Stuck opened" 0 "Normal" ;
VAL_ 791 bms_demConStuckClosed 1 "Stuck closed" 0 "Normal" ;
VAL_ 791 bms_demPackFuseBlow 0 "Normal" 3 "Fault" ;
VAL_ 791 bms_demPackFuseResistance 0 "Normal" 3 "Fault" ;
VAL_ 791 bms_demPackFuseOverCurrent 0 "Normal" 3 "Fault" ;
VAL_ 791 bms_demPackFETTemperature 0 "Normal" 3 "Fault" ;
VAL_ 803 bms_rentalinfo_expired 0 "AVAILABLE" 1 "EXPIRED" ;
VAL_ 806 bms_statustrust_bms1charger 0 "READY" 1 "PASS" 2 "FAIL" 3 "PROCESSING" 4 "TIMEOUT" ;
VAL_ 806 bms_statustrust_bms0charger 0 "READY" 1 "PASS" 2 "FAIL" 3 "PROCESSING" 4 "TIMEOUT" ;
VAL_ 806 bms_statustrust_bms3charger 0 "READY" 1 "PASS" 2 "FAIL" 3 "PROCESSING" 4 "TIMEOUT" ;
VAL_ 806 bms_statustrust_bms2charger 0 "READY" 1 "PASS" 2 "FAIL" 3 "PROCESSING" 4 "TIMEOUT" ;
VAL_ 806 bms_resulttrust_bms1charger 0 "READY" 1 "PASS" 2 "FAIL" 3 "PROCESSING" 4 "TIMEOUT" ;
VAL_ 806 bms_resulttrust_bms0charger 0 "READY" 1 "PASS" 2 "FAIL" 3 "PROCESSING" 4 "TIMEOUT" ;
VAL_ 806 bms_resulttrust_bms3charger 0 "READY" 1 "PASS" 2 "FAIL" 3 "PROCESSING" 4 "TIMEOUT" ;
VAL_ 806 bms_resulttrust_bms2charger 0 "READY" 1 "PASS" 2 "FAIL" 3 "PROCESSING" 4 "TIMEOUT" ;
VAL_ 806 bms_statustrust_bms1cbox 0 "READY" 1 "PASS" 2 "FAIL" 3 "PROCESSING" 4 "TIMEOUT" ;
VAL_ 806 bms_statustrust_bms0cbox 0 "READY" 1 "PASS" 2 "FAIL" 3 "PROCESSING" 4 "TIMEOUT" ;
VAL_ 806 bms_statustrust_bms3cbox 0 "READY" 1 "PASS" 2 "FAIL" 3 "PROCESSING" 4 "TIMEOUT" ;
VAL_ 806 bms_statustrust_bms2cbox 0 "READY" 1 "PASS" 2 "FAIL" 3 "PROCESSING" 4 "TIMEOUT" ;
VAL_ 806 bms_resulttrust_bms1cbox 0 "READY" 1 "PASS" 2 "FAIL" 3 "PROCESSING" 4 "TIMEOUT" ;
VAL_ 806 bms_resulttrust_bms0cbox 0 "READY" 1 "PASS" 2 "FAIL" 3 "PROCESSING" 4 "TIMEOUT" ;
VAL_ 806 bms_resulttrust_bms3cbox 0 "READY" 1 "PASS" 2 "FAIL" 3 "PROCESSING" 4 "TIMEOUT" ;
VAL_ 806 bms_resulttrust_bms2cbox 0 "READY" 1 "PASS" 2 "FAIL" 3 "PROCESSING" 4 "TIMEOUT" ;
VAL_ 807 bms_demParallelOvrdSlave 0 "Normal" 1 "Warning1" ;
VAL_ 807 bms_demParallelOvrdMaster 0 "Normal" 1 "Warning1" ;
VAL_ 807 bms_demParallelDiffVoltage 0 "Normal" 1 "Warning1" ;
VAL_ 807 bms_demParallelDiffCurrent 0 "Normal" 1 "Warning1" ;
VAL_ 807 bms_demParallelDiffSOC 0 "Normal" 1 "Warning1" ;
VAL_ 807 bms_demParallelDiffTemp 0 "Normal" 1 "Warning1" ;
VAL_ 807 bms_demParallelDiffVer 0 "Normal" 1 "Warning1" ;
VAL_ 807 bms_demParallelDiffSOH 0 "Normal" 1 "Warning1" ;
VAL_ 1281 charger_fastchargemode 0 "Normal charging" 1 "Fast charging" ;
VAL_ 1281 charger_runmode 0 "Reserver1" 1 "Precharge mode" 2 "Constant current mode" 3 "Constant voltage mode" 4 "Protectected" ;
VAL_ 1282 charger_type 0 "RVSD" 1 "OBC (Portable charger)" 2 "Charging station" 3 "Battery station" ;
VAL_ 1282 charger_controlmode_bms 0 "Go to Standby" 1 "Go to TrustVHC Mode" 2 "Go to TrustCHG Mode" 3 "Go to Working Mode" 4 "Go to Sleep Mode" 5 "Go to Shutdown Mode" 6 "Go to VF Setting Mode" ;
VAL_ 1282 charger_statustrust_bms1 0 "Stop" 1 "Start" 2 "RSVD1" 3 "RSVD2" ;
VAL_ 1282 charger_statustrust_bms0 0 "READY" 1 "PASS" 2 "FAIL" 3 "PROCESSING" 4 "TIMEOUT" ;
VAL_ 1282 charger_statustrust_bms3 0 "READY" 1 "PASS" 2 "FAIL" 3 "PROCESSING" 4 "TIMEOUT" ;
VAL_ 1282 charger_statustrust_bms2 0 "READY" 1 "PASS" 2 "FAIL" 3 "PROCESSING" 4 "TIMEOUT" ;
VAL_ 1282 charger_resulttrust_bms1 0 "READY" 1 "PASS" 2 "FAIL" 3 "PROCESSING" 4 "TIMEOUT" ;
VAL_ 1282 charger_resulttrust_bms0 0 "READY" 1 "PASS" 2 "FAIL" 3 "PROCESSING" 4 "TIMEOUT" ;
VAL_ 1282 charger_resulttrust_bms3 0 "READY" 1 "PASS" 2 "FAIL" 3 "PROCESSING" 4 "TIMEOUT" ;
VAL_ 1282 charger_resulttrust_bms2 0 "READY" 1 "PASS" 2 "FAIL" 3 "PROCESSING" 4 "TIMEOUT" ;
VAL_ 1282 charger_commrequired_bms 0 "Stop" 1 "Start" 2 "RSVD1" 3 "RSVD2" ;
